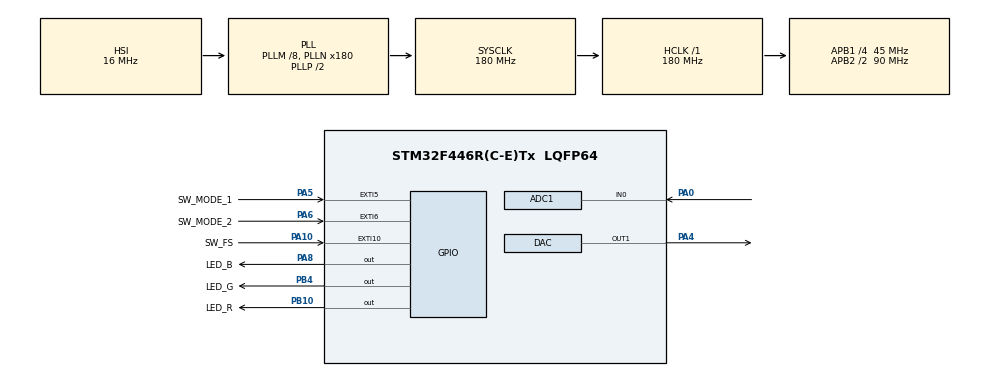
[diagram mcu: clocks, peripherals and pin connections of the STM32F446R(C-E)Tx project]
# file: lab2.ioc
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ADC1.Channel-0\#ChannelRegularConversion=ADC_CHANNEL_0
ADC1.DMAContinuousRequests=ENABLE
ADC1.ExternalTrigConv=ADC_EXTERNALTRIGCONV_T2_TRGO
ADC1.InjNumberOfConversion=0
ADC1.NbrOfConversionFlag=1
ADC1.Rank-0\#ChannelRegularConversion=1
ADC1.SamplingTime-0\#ChannelRegularConversion=ADC_SAMPLETIME_3CYCLES
ADC1.master=1
DAC.DAC_Trigger=DAC_TRIGGER_T2_TRGO
Dma.ADC1.0.Direction=DMA_PERIPH_TO_MEMORY
Dma.ADC1.0.FIFOMode=DMA_FIFOMODE_DISABLE
Dma.ADC1.0.Instance=DMA2_Stream0
Dma.ADC1.0.MemDataAlignment=DMA_MDATAALIGN_HALFWORD
Dma.ADC1.0.MemInc=DMA_MINC_ENABLE
Dma.ADC1.0.Mode=DMA_CIRCULAR
Dma.ADC1.0.PeriphDataAlignment=DMA_PDATAALIGN_HALFWORD
Dma.ADC1.0.PeriphInc=DMA_PINC_DISABLE
Dma.ADC1.0.Priority=DMA_PRIORITY_HIGH
Dma.DAC1.1.Direction=DMA_MEMORY_TO_PERIPH
Dma.DAC1.1.FIFOMode=DMA_FIFOMODE_DISABLE
Dma.DAC1.1.Instance=DMA1_Stream5
Dma.DAC1.1.MemDataAlignment=DMA_MDATAALIGN_HALFWORD
Dma.DAC1.1.MemInc=DMA_MINC_ENABLE
Dma.DAC1.1.Mode=DMA_CIRCULAR
Dma.DAC1.1.PeriphDataAlignment=DMA_PDATAALIGN_HALFWORD
Dma.DAC1.1.PeriphInc=DMA_PINC_DISABLE
Dma.DAC1.1.Priority=DMA_PRIORITY_HIGH
Dma.Request0=ADC1
Dma.Request1=DAC1
Mcu.Family=STM32F4
Mcu.Name=STM32F446R(C-E)Tx
Mcu.Package=LQFP64
NVIC.DMA1_Stream5_IRQn=true\:0\:0\:false\:false\:true\:false\:true\:true
NVIC.DMA2_Stream0_IRQn=true\:0\:0\:false\:false\:true\:false\:true\:true
NVIC.EXTI15_10_IRQn=true\:0\:0\:false\:false\:true\:true\:true\:true
NVIC.EXTI9_5_IRQn=true\:0\:0\:false\:false\:true\:true\:true\:true
NVIC.PriorityGroup=NVIC_PRIORITYGROUP_0
PA0-WKUP.Signal=ADCx_IN0
PA10.GPIO_Label=SW_FS
PA10.Signal=GPXTI10
PA13.GPIO_Label=TMS
PA13.Mode=Serial_Wire
PA13.Signal=SYS_JTMS-SWDIO
PA14.GPIO_Label=TCK
PA14.Mode=Serial_Wire
PA14.Signal=SYS_JTCK-SWCLK
PA4.Signal=COMP_DAC1_group
PA5.GPIO_Label=SW_MODE_1
PA5.Signal=GPXTI5
PA6.GPIO_Label=SW_MODE_2
PA6.Signal=GPXTI6
PA8.GPIO_Label=LED_B
PA8.Signal=GPIO_Output
PB10.GPIO_Label=LED_R
PB10.Signal=GPIO_Output
PB3.GPIO_Label=SWO
PB3.Signal=SYS_JTDO-SWO
PB4.GPIO_Label=LED_G
PB4.Signal=GPIO_Output
PC14-OSC32_IN.Mode=LSE-External-Oscillator
PC14-OSC32_IN.Signal=RCC_OSC32_IN
PC15-OSC32_OUT.Mode=LSE-External-Oscillator
PC15-OSC32_OUT.Signal=RCC_OSC32_OUT
PH0-OSC_IN.Mode=HSE-External-Oscillator
PH0-OSC_IN.Signal=RCC_OSC_IN
PH1-OSC_OUT.Mode=HSE-External-Oscillator
PH1-OSC_OUT.Signal=RCC_OSC_OUT
ProjectManager.HeapSize=0x200
ProjectManager.StackSize=0x400
ProjectManager.TargetToolchain=STM32CubeIDE
RCC.48MHZClocksFreq_Value=84000000
RCC.AHBFreq_Value=180000000
RCC.APB1CLKDivider=RCC_HCLK_DIV4
RCC.APB1Freq_Value=45000000
RCC.APB1TimFreq_Value=90000000
RCC.APB2CLKDivider=RCC_HCLK_DIV2
RCC.APB2Freq_Value=90000000
RCC.APB2TimFreq_Value=180000000
RCC.CortexFreq_Value=180000000
RCC.FLatency-AdvancedSettings=FLASH_LATENCY_5
RCC.HCLKFreq_Value=180000000
RCC.HSE_VALUE=8000000
RCC.HSI_VALUE=16000000
RCC.PLLM=8
RCC.PLLN=180
RCC.SYSCLKFreq_VALUE=180000000
RCC.SYSCLKSource=RCC_SYSCLKSOURCE_PLLCLK
RCC.USBFreq_Value=180000000
RCC.VCOOutputFreq_Value=360000000
SH.ADCx_IN0.0=ADC1_IN0,IN0
SH.COMP_DAC1_group.0=DAC_OUT1,DAC_OUT1
TIM2.AutoReloadPreload=TIM_AUTORELOAD_PRELOAD_ENABLE
TIM2.Period=11249
TIM2.TIM_MasterOutputTrigger=TIM_TRGO_UPDATE
VP_TIM2_VS_ClockSourceINT.Mode=Internal
board=NUCLEO-F446RE

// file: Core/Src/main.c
/**
 ******************************************************************************
 * @file           : main.c
 * @brief          : Real-Time Signal Acquisition and Filtering using STM32F446RE
 *
 * This program implements a real-time digital signal processing (DSP) pipeline
 * on the STM32F446RE microcontroller. It captures analog input via ADC, processes
 * the signal in Q15 fixed-point format using biquad IIR filters (LP, HP, BP, BS),
 * and outputs the result through the DAC using DMA. The sampling rate (8–48 kHz)
 * and filter type are dynamically selectable using external GPIO interrupts.
 *
 * Key Features:
 * - Double-buffered ADC/DAC using DMA for real-time throughput
 * - Q15 format filtering with CMSIS-DSP `arm_biquad_cascade_df1_q15`
 * - Dynamic selection of filter type and sampling frequency via GPIO
 * - Processing time profiling using DWT->CYCCNT
 * - Visual feedback using RGB LEDs
 *
 * Author          : Campos Mariano
 * Date            : 24/06/2025
 ******************************************************************************
 */

/* USER CODE END Header */
#include "main.h"
#include "adc.h"
#include "dac.h"
#include "dma.h"
#include "tim.h"
#include "gpio.h"
#include "arm_math.h" // CMSIS-DSP library for fixed-point processing

/* USER CODE END Includes */

/* USER CODE BEGIN PD */
#define BUFFER_SIZE 512     // Size of ADC/DAC/Q15 buffers
#define FS_8K   11249       // Auto-reload value for TIM2 to achieve ~8kHz sampling with 90 MHz clock
#define DEBOUNCE_DELAY 200	// Time anti-bounce
#define Num_coef_FPB	128
#define Num_coef_FPA	512
#define Num_coef_FPBD	1024
#define Num_coef_FRBD	1024
/* USER CODE END PD */

/* USER CODE BEGIN PM */
arm_fir_instance_q15 Filtro;
/* USER CODE END PM */

/* USER CODE BEGIN PV */
extern TIM_HandleTypeDef htim2;      // Timer used for triggering ADC/DAC
extern ADC_HandleTypeDef hadc1;      // ADC handle
extern DAC_HandleTypeDef hdac;       // DAC handle

uint16_t adc_buffer[BUFFER_SIZE];    // Raw ADC samples
uint16_t dac_buffer[BUFFER_SIZE];    // Output buffer for DAC
q15_t q15_buffer[BUFFER_SIZE];       // Intermediate Q15 format buffer
uint8_t fs_mode = 0;                 // Sampling frequency mode selector (0–5)
uint32_t time = 0;                   // Variable to store CPU cycles for processing time profiling
uint8_t filter_type = 0;			 // type of the filter LP,HP,BP,BS
uint32_t last_interrupt_time = 0;    // Time of the last interrupt anti-bouncing

uint32_t FPB_status[Num_coef_FPB + (BUFFER_SIZE/2) -1];
uint32_t FPA_status[Num_coef_FPB + (BUFFER_SIZE/2) -1];
uint32_t FPBD_status[Num_coef_FPB + (BUFFER_SIZE/2) -1];
uint32_t FRBD_status[Num_coef_FPB + (BUFFER_SIZE/2) -1];

// ===== LOWPASS Filter =====
// fs = 8000 Hz
const q15_t FIR_FPB_Coef_8K[Num_coef_FPB + 1] = {
        -4,      6,     -9,     12,    -14,     16,    -17,     16,
       -14,     11,     -6,     -2,     10,    -20,     31,    -41,
        51,    -59,     65,    -66,     64,    -56,     43,    -25,
         3,     24,    -54,     85,   -116,    143,   -166,    180,
      -186,    180,   -161,    129,    -83,     26,     42,   -117,
       195,   -273,    345,   -406,    450,   -473,    468,   -433,
       364,   -259,    119,     56,   -262,    496,   -750,   1018,
     -1292,   1563,  -1821,   2058,  -2265,   2434,  -2560,   2638,
     32767,   2638,  -2560,   2434,  -2265,   2058,  -1821,   1563,
     -1292,   1018,   -750,    496,   -262,     56,    119,   -259,
       364,   -433,    468,   -473,    450,   -406,    345,   -273,
       195,   -117,     42,     26,    -83,    129,   -161,    180,
      -186,    180,   -166,    143,   -116,     85,    -54,     24,
         3,    -25,     43,    -56,     64,    -66,     65,    -59,
        51,    -41,     31,    -20,     10,     -2,     -6,     11,
       -14,     16,    -17,     16,    -14,     12,     -9,      6,
        -4
};

// ===== LOWPASS Filter =====
// fs = 16000 Hz
const q15_t FIR_FPB_Coef_16K[Num_coef_FPB + 1] = {
       -82,    -38,     86,     65,    -82,    -96,     70,    126,
       -48,   -155,     15,    178,     28,   -193,    -79,    196,
       137,   -184,   -198,    155,    258,   -108,   -313,     42,
       356,     42,   -384,   -141,    389,    252,   -367,   -369,
       314,    485,   -227,   -593,    104,    684,     54,   -747,
      -246,    773,    467,   -751,   -714,    669,    978,   -517,
     -1251,    279,   1524,     62,  -1787,   -536,   2030,   1196,
     -2244,  -2157,   2421,   3724,  -2552,  -7036,   2633,  22392,
     32767,  22392,   2633,  -7036,  -2552,   3724,   2421,  -2157,
     -2244,   1196,   2030,   -536,  -1787,     62,   1524,    279,
     -1251,   -517,    978,    669,   -714,   -751,    467,    773,
      -246,   -747,     54,    684,    104,   -593,   -227,    485,
       314,   -369,   -367,    252,    389,   -141,   -384,     42,
       356,     42,   -313,   -108,    258,    155,   -198,   -184,
       137,    196,    -79,   -193,     28,    178,     15,   -155,
       -48,    126,     70,    -96,    -82,     65,     86,    -38,
       -82
};

// ===== LOWPASS Filter =====
// fs = 22000 Hz
const q15_t FIR_FPB_Coef_22K[Num_coef_FPB + 1] = {
      -182,   -245,    -91,    160,    289,    167,   -117,   -320,
      -251,     51,    333,    338,     38,   -321,   -420,   -147,
       281,    490,    274,   -207,   -540,   -413,     98,    562,
       556,     48,   -546,   -695,   -229,    484,    820,    443,
      -368,   -917,   -684,    190,    973,    945,     56,   -973,
     -1219,   -378,    899,   1495,    788,   -728,  -1763,  -1304,
       427,   2012,   1961,     61,  -2232,  -2842,   -856,   2414,
      4163,   2283,  -2551,  -6683,  -5641,   2635,  15786,  27876,
     32767,  27876,  15786,   2635,  -5641,  -6683,  -2551,   2283,
      4163,   2414,   -856,  -2842,  -2232,     61,   1961,   2012,
       427,  -1304,  -1763,   -728,    788,   1495,    899,   -378,
     -1219,   -973,     56,    945,    973,    190,   -684,   -917,
      -368,    443,    820,    484,   -229,   -695,   -546,     48,
       556,    562,     98,   -413,   -540,   -207,    274,    490,
       281,   -147,   -420,   -321,     38,    338,    333,     51,
      -251,   -320,   -117,    167,    289,    160,    -91,   -245,
      -182
};

// ===== LOWPASS Filter =====
// fs = 44000 Hz
const q15_t FIR_FPB_Coef_44K[Num_coef_FPB + 1] = {
      -308,   -570,   -655,   -523,   -207,    197,    558,    750,
       700,    410,    -35,   -494,   -812,   -874,   -645,   -183,
       367,    827,   1034,    903,    459,   -169,   -778,  -1163,
     -1178,   -794,   -115,    648,   1244,   1458,   1191,    499,
      -414,  -1254,  -1732,  -1655,  -1007,     41,   1165,   1989,
      2205,   1683,    529,   -927,  -2217,  -2884,  -2625,  -1418,
       443,   2407,   3813,   4090,   2955,    548,  -2550,  -5414,
     -7001,  -6413,  -3166,   2638,  10272,  18508,  25868,  30953,
     32767,  30953,  25868,  18508,  10272,   2638,  -3166,  -6413,
     -7001,  -5414,  -2550,    548,   2955,   4090,   3813,   2407,
       443,  -1418,  -2625,  -2884,  -2217,   -927,    529,   1683,
      2205,   1989,   1165,     41,  -1007,  -1655,  -1732,  -1254,
      -414,    499,   1191,   1458,   1244,    648,   -115,   -794,
     -1178,  -1163,   -778,   -169,    459,    903,   1034,    827,
       367,   -183,   -645,   -874,   -812,   -494,    -35,    410,
       700,    750,    558,    197,   -207,   -523,   -655,   -570,
      -308
};

// ===== LOWPASS Filter =====
// fs = 48000 Hz
const q15_t FIR_FPB_Coef_48K[Num_coef_FPB + 1] = {
      -343,   -666,   -848,   -839,   -632,   -264,    184,    611,
       916,   1021,    889,    541,     47,   -485,   -930,  -1180,
     -1164,   -872,   -357,    271,    871,   1300,   1445,   1257,
       760,     51,   -714,  -1358,  -1722,  -1700,  -1272,   -511,
       425,   1328,   1981,   2211,   1930,   1164,     54,  -1165,
     -2213,  -2825,  -2815,  -2124,   -844,    781,   2405,   3641,
      4144,   3696,   2270,     56,  -2550,  -4996,  -6673,  -7018,
     -5631,  -2362,   2639,   8921,  15786,  22391,  27876,  31501,
     32767,  31501,  27876,  22391,  15786,   8921,   2639,  -2362,
     -5631,  -7018,  -6673,  -4996,  -2550,     56,   2270,   3696,
      4144,   3641,   2405,    781,   -844,  -2124,  -2815,  -2825,
     -2213,  -1165,     54,   1164,   1930,   2211,   1981,   1328,
       425,   -511,  -1272,  -1700,  -1722,  -1358,   -714,     51,
       760,   1257,   1445,   1300,    871,    271,   -357,   -872,
     -1164,  -1180,   -930,   -485,     47,    541,    889,   1021,
       916,    611,    184,   -264,   -632,   -839,   -848,   -666,
      -343
};

// ===== HIGHPASS Filter =====
// fs = 8000 Hz
const q15_t FIR_FPA_Coef_8K[Num_coef_FPA + 1] = {
        -1,     -1,     -1,     -1,     -1,     -1,     -1,     -2,
        -2,     -2,     -2,     -2,     -2,     -2,     -3,     -3,
        -3,     -3,     -3,     -4,     -4,     -4,     -4,     -4,
        -5,     -5,     -5,     -5,     -5,     -6,     -6,     -6,
        -6,     -6,     -7,     -7,     -7,     -7,     -7,     -7,
        -8,     -8,     -8,     -8,     -8,     -8,     -8,     -8,
        -8,     -9,     -9,     -9,     -9,     -9,     -9,     -9,
        -9,     -8,     -8,     -8,     -8,     -8,     -8,     -8,
        -7,     -7,     -7,     -6,     -6,     -6,     -5,     -5,
        -5,     -4,     -4,     -3,     -2,     -2,     -1,     -1,
         0,      1,      1,      2,      3,      4,      5,      5,
         6,      7,      8,      9,     10,     11,     12,     13,
        14,     15,     16,     17,     18,     20,     21,     22,
        23,     24,     25,     26,     27,     29,     30,     31,
        32,     33,     34,     35,     36,     37,     38,     39,
        40,     41,     42,     43,     43,     44,     45,     45,
        46,     47,     47,     47,     48,     48,     48,     48,
        49,     49,     48,     48,     48,     48,     47,     47,
        46,     46,     45,     44,     43,     42,     41,     39,
        38,     36,     35,     33,     31,     29,     27,     25,
        23,     20,     18,     15,     12,      9,      6,      3,
         0,     -3,     -7,    -10,    -14,    -18,    -22,    -26,
       -30,    -34,    -38,    -43,    -47,    -52,    -57,    -61,
       -66,    -71,    -76,    -82,    -87,    -92,    -98,   -103,
      -108,   -114,   -120,   -125,   -131,   -137,   -143,   -148,
      -154,   -160,   -166,   -172,   -178,   -184,   -190,   -196,
      -201,   -207,   -213,   -219,   -225,   -231,   -236,   -242,
      -248,   -253,   -259,   -264,   -269,   -275,   -280,   -285,
      -290,   -295,   -300,   -304,   -309,   -313,   -318,   -322,
      -326,   -330,   -334,   -338,   -341,   -344,   -348,   -351,
      -354,   -356,   -359,   -361,   -364,   -366,   -368,   -369,
      -371,   -372,   -374,   -375,   -375,   -376,   -376,   -377,
     32767,   -377,   -376,   -376,   -375,   -375,   -374,   -372,
      -371,   -369,   -368,   -366,   -364,   -361,   -359,   -356,
      -354,   -351,   -348,   -344,   -341,   -338,   -334,   -330,
      -326,   -322,   -318,   -313,   -309,   -304,   -300,   -295,
      -290,   -285,   -280,   -275,   -269,   -264,   -259,   -253,
      -248,   -242,   -236,   -231,   -225,   -219,   -213,   -207,
      -201,   -196,   -190,   -184,   -178,   -172,   -166,   -160,
      -154,   -148,   -143,   -137,   -131,   -125,   -120,   -114,
      -108,   -103,    -98,    -92,    -87,    -82,    -76,    -71,
       -66,    -61,    -57,    -52,    -47,    -43,    -38,    -34,
       -30,    -26,    -22,    -18,    -14,    -10,     -7,     -3,
         0,      3,      6,      9,     12,     15,     18,     20,
        23,     25,     27,     29,     31,     33,     35,     36,
        38,     39,     41,     42,     43,     44,     45,     46,
        46,     47,     47,     48,     48,     48,     48,     49,
        49,     48,     48,     48,     48,     47,     47,     47,
        46,     45,     45,     44,     43,     43,     42,     41,
        40,     39,     38,     37,     36,     35,     34,     33,
        32,     31,     30,     29,     27,     26,     25,     24,
        23,     22,     21,     20,     18,     17,     16,     15,
        14,     13,     12,     11,     10,      9,      8,      7,
         6,      5,      5,      4,      3,      2,      1,      1,
         0,     -1,     -1,     -2,     -2,     -3,     -4,     -4,
        -5,     -5,     -5,     -6,     -6,     -6,     -7,     -7,
        -7,     -8,     -8,     -8,     -8,     -8,     -8,     -8,
        -9,     -9,     -9,     -9,     -9,     -9,     -9,     -9,
        -8,     -8,     -8,     -8,     -8,     -8,     -8,     -8,
        -8,     -7,     -7,     -7,     -7,     -7,     -7,     -6,
        -6,     -6,     -6,     -6,     -5,     -5,     -5,     -5,
        -5,     -4,     -4,     -4,     -4,     -4,     -3,     -3,
        -3,     -3,     -3,     -2,     -2,     -2,     -2,     -2,
        -2,     -2,     -1,     -1,     -1,     -1,     -1,     -1,
        -1
};

// ===== HIGHPASS Filter =====
// fs = 16000 Hz
const q15_t FIR_FPA_Coef_16K[Num_coef_FPA + 1] = {
         9,      9,      9,      9,      9,      9,     10,     10,
        10,     10,     10,     11,     11,     11,     11,     11,
        11,     11,     12,     12,     12,     12,     12,     12,
        12,     12,     12,     13,     13,     13,     13,     13,
        13,     13,     13,     13,     13,     13,     13,     13,
        13,     13,     13,     13,     13,     13,     12,     12,
        12,     12,     12,     12,     12,     11,     11,     11,
        11,     11,     10,     10,     10,     10,      9,      9,
         9,      8,      8,      8,      7,      7,      6,      6,
         6,      5,      5,      4,      4,      3,      3,      2,
         1,      1,      0,      0,     -1,     -2,     -2,     -3,
        -4,     -4,     -5,     -6,     -7,     -7,     -8,     -9,
       -10,    -11,    -12,    -12,    -13,    -14,    -15,    -16,
       -17,    -18,    -19,    -20,    -21,    -22,    -23,    -24,
       -25,    -26,    -28,    -29,    -30,    -31,    -32,    -33,
       -35,    -36,    -37,    -38,    -40,    -41,    -42,    -43,
       -45,    -46,    -47,    -49,    -50,    -51,    -53,    -54,
       -56,    -57,    -58,    -60,    -61,    -63,    -64,    -66,
       -67,    -69,    -70,    -72,    -73,    -75,    -76,    -78,
       -79,    -81,    -82,    -84,    -85,    -87,    -88,    -90,
       -91,    -93,    -94,    -96,    -97,    -99,   -101,   -102,
      -104,   -105,   -107,   -108,   -110,   -111,   -113,   -114,
      -116,   -117,   -119,   -120,   -122,   -123,   -125,   -126,
      -128,   -129,   -131,   -132,   -134,   -135,   -136,   -138,
      -139,   -141,   -142,   -143,   -145,   -146,   -147,   -149,
      -150,   -151,   -152,   -154,   -155,   -156,   -157,   -158,
      -160,   -161,   -162,   -163,   -164,   -165,   -166,   -167,
      -168,   -169,   -170,   -171,   -172,   -173,   -174,   -174,
      -175,   -176,   -177,   -178,   -178,   -179,   -180,   -180,
      -181,   -182,   -182,   -183,   -183,   -184,   -184,   -185,
      -185,   -186,   -186,   -186,   -187,   -187,   -187,   -188,
      -188,   -188,   -188,   -188,   -188,   -189,   -189,   -189,
     32767,   -189,   -189,   -189,   -188,   -188,   -188,   -188,
      -188,   -188,   -187,   -187,   -187,   -186,   -186,   -186,
      -185,   -185,   -184,   -184,   -183,   -183,   -182,   -182,
      -181,   -180,   -180,   -179,   -178,   -178,   -177,   -176,
      -175,   -174,   -174,   -173,   -172,   -171,   -170,   -169,
      -168,   -167,   -166,   -165,   -164,   -163,   -162,   -161,
      -160,   -158,   -157,   -156,   -155,   -154,   -152,   -151,
      -150,   -149,   -147,   -146,   -145,   -143,   -142,   -141,
      -139,   -138,   -136,   -135,   -134,   -132,   -131,   -129,
      -128,   -126,   -125,   -123,   -122,   -120,   -119,   -117,
      -116,   -114,   -113,   -111,   -110,   -108,   -107,   -105,
      -104,   -102,   -101,    -99,    -97,    -96,    -94,    -93,
       -91,    -90,    -88,    -87,    -85,    -84,    -82,    -81,
       -79,    -78,    -76,    -75,    -73,    -72,    -70,    -69,
       -67,    -66,    -64,    -63,    -61,    -60,    -58,    -57,
       -56,    -54,    -53,    -51,    -50,    -49,    -47,    -46,
       -45,    -43,    -42,    -41,    -40,    -38,    -37,    -36,
       -35,    -33,    -32,    -31,    -30,    -29,    -28,    -26,
       -25,    -24,    -23,    -22,    -21,    -20,    -19,    -18,
       -17,    -16,    -15,    -14,    -13,    -12,    -12,    -11,
       -10,     -9,     -8,     -7,     -7,     -6,     -5,     -4,
        -4,     -3,     -2,     -2,     -1,      0,      0,      1,
         1,      2,      3,      3,      4,      4,      5,      5,
         6,      6,      6,      7,      7,      8,      8,      8,
         9,      9,      9,     10,     10,     10,     10,     11,
        11,     11,     11,     11,     12,     12,     12,     12,
        12,     12,     12,     13,     13,     13,     13,     13,
        13,     13,     13,     13,     13,     13,     13,     13,
        13,     13,     13,     13,     13,     13,     12,     12,
        12,     12,     12,     12,     12,     12,     12,     11,
        11,     11,     11,     11,     11,     11,     10,     10,
        10,     10,     10,      9,      9,      9,      9,      9,
         9
};

// ===== HIGHPASS Filter =====
// fs = 24000 Hz
const q15_t FIR_FPA_Coef_22K[Num_coef_FPA + 1] = {
        -7,     -7,     -7,     -8,     -8,     -8,     -8,     -9,
        -9,     -9,    -10,    -10,    -10,    -11,    -11,    -11,
       -12,    -12,    -12,    -13,    -13,    -13,    -14,    -14,
       -15,    -15,    -15,    -16,    -16,    -16,    -17,    -17,
       -18,    -18,    -18,    -19,    -19,    -20,    -20,    -21,
       -21,    -21,    -22,    -22,    -23,    -23,    -24,    -24,
       -25,    -25,    -26,    -26,    -26,    -27,    -27,    -28,
       -28,    -29,    -29,    -30,    -30,    -31,    -31,    -32,
       -32,    -33,    -34,    -34,    -35,    -35,    -36,    -36,
       -37,    -37,    -38,    -38,    -39,    -39,    -40,    -41,
       -41,    -42,    -42,    -43,    -43,    -44,    -45,    -45,
       -46,    -46,    -47,    -47,    -48,    -49,    -49,    -50,
       -50,    -51,    -52,    -52,    -53,    -53,    -54,    -55,
       -55,    -56,    -56,    -57,    -58,    -58,    -59,    -59,
       -60,    -61,    -61,    -62,    -62,    -63,    -64,    -64,
       -65,    -65,    -66,    -67,    -67,    -68,    -69,    -69,
       -70,    -70,    -71,    -72,    -72,    -73,    -73,    -74,
       -75,    -75,    -76,    -76,    -77,    -77,    -78,    -79,
       -79,    -80,    -80,    -81,    -82,    -82,    -83,    -83,
       -84,    -84,    -85,    -85,    -86,    -87,    -87,    -88,
       -88,    -89,    -89,    -90,    -90,    -91,    -91,    -92,
       -92,    -93,    -93,    -94,    -94,    -95,    -95,    -96,
       -96,    -97,    -97,    -98,    -98,    -99,    -99,   -100,
      -100,   -101,   -101,   -102,   -102,   -102,   -103,   -103,
      -104,   -104,   -104,   -105,   -105,   -106,   -106,   -106,
      -107,   -107,   -107,   -108,   -108,   -108,   -109,   -109,
      -109,   -110,   -110,   -110,   -111,   -111,   -111,   -112,
      -112,   -112,   -112,   -113,   -113,   -113,   -113,   -114,
      -114,   -114,   -114,   -114,   -115,   -115,   -115,   -115,
      -115,   -115,   -116,   -116,   -116,   -116,   -116,   -116,
      -116,   -117,   -117,   -117,   -117,   -117,   -117,   -117,
      -117,   -117,   -117,   -117,   -117,   -117,   -117,   -117,
     32767,   -117,   -117,   -117,   -117,   -117,   -117,   -117,
      -117,   -117,   -117,   -117,   -117,   -117,   -117,   -117,
      -116,   -116,   -116,   -116,   -116,   -116,   -116,   -115,
      -115,   -115,   -115,   -115,   -115,   -114,   -114,   -114,
      -114,   -114,   -113,   -113,   -113,   -113,   -112,   -112,
      -112,   -112,   -111,   -111,   -111,   -110,   -110,   -110,
      -109,   -109,   -109,   -108,   -108,   -108,   -107,   -107,
      -107,   -106,   -106,   -106,   -105,   -105,   -104,   -104,
      -104,   -103,   -103,   -102,   -102,   -102,   -101,   -101,
      -100,   -100,    -99,    -99,    -98,    -98,    -97,    -97,
       -96,    -96,    -95,    -95,    -94,    -94,    -93,    -93,
       -92,    -92,    -91,    -91,    -90,    -90,    -89,    -89,
       -88,    -88,    -87,    -87,    -86,    -85,    -85,    -84,
       -84,    -83,    -83,    -82,    -82,    -81,    -80,    -80,
       -79,    -79,    -78,    -77,    -77,    -76,    -76,    -75,
       -75,    -74,    -73,    -73,    -72,    -72,    -71,    -70,
       -70,    -69,    -69,    -68,    -67,    -67,    -66,    -65,
       -65,    -64,    -64,    -63,    -62,    -62,    -61,    -61,
       -60,    -59,    -59,    -58,    -58,    -57,    -56,    -56,
       -55,    -55,    -54,    -53,    -53,    -52,    -52,    -51,
       -50,    -50,    -49,    -49,    -48,    -47,    -47,    -46,
       -46,    -45,    -45,    -44,    -43,    -43,    -42,    -42,
       -41,    -41,    -40,    -39,    -39,    -38,    -38,    -37,
       -37,    -36,    -36,    -35,    -35,    -34,    -34,    -33,
       -32,    -32,    -31,    -31,    -30,    -30,    -29,    -29,
       -28,    -28,    -27,    -27,    -26,    -26,    -26,    -25,
       -25,    -24,    -24,    -23,    -23,    -22,    -22,    -21,
       -21,    -21,    -20,    -20,    -19,    -19,    -18,    -18,
       -18,    -17,    -17,    -16,    -16,    -16,    -15,    -15,
       -15,    -14,    -14,    -13,    -13,    -13,    -12,    -12,
       -12,    -11,    -11,    -11,    -10,    -10,    -10,     -9,
        -9,     -9,     -8,     -8,     -8,     -8,     -7,     -7,
        -7
};

// ===== HIGHPASS Filter =====
// fs = 44000 Hz
const q15_t FIR_FPA_Coef_44K[Num_coef_FPA + 1] = {
       -27,    -27,    -28,    -28,    -28,    -28,    -29,    -29,
       -29,    -30,    -30,    -30,    -30,    -31,    -31,    -31,
       -32,    -32,    -32,    -33,    -33,    -33,    -33,    -34,
       -34,    -34,    -35,    -35,    -35,    -36,    -36,    -36,
       -37,    -37,    -37,    -37,    -38,    -38,    -38,    -39,
       -39,    -39,    -40,    -40,    -40,    -41,    -41,    -41,
       -41,    -42,    -42,    -42,    -43,    -43,    -43,    -44,
       -44,    -44,    -45,    -45,    -45,    -45,    -46,    -46,
       -46,    -47,    -47,    -47,    -48,    -48,    -48,    -48,
       -49,    -49,    -49,    -50,    -50,    -50,    -51,    -51,
       -51,    -52,    -52,    -52,    -52,    -53,    -53,    -53,
       -54,    -54,    -54,    -54,    -55,    -55,    -55,    -56,
       -56,    -56,    -57,    -57,    -57,    -57,    -58,    -58,
       -58,    -59,    -59,    -59,    -59,    -60,    -60,    -60,
       -60,    -61,    -61,    -61,    -62,    -62,    -62,    -62,
       -63,    -63,    -63,    -63,    -64,    -64,    -64,    -64,
       -65,    -65,    -65,    -65,    -66,    -66,    -66,    -66,
       -67,    -67,    -67,    -67,    -68,    -68,    -68,    -68,
       -69,    -69,    -69,    -69,    -70,    -70,    -70,    -70,
       -70,    -71,    -71,    -71,    -71,    -72,    -72,    -72,
       -72,    -72,    -73,    -73,    -73,    -73,    -73,    -74,
       -74,    -74,    -74,    -74,    -75,    -75,    -75,    -75,
       -75,    -75,    -76,    -76,    -76,    -76,    -76,    -76,
       -77,    -77,    -77,    -77,    -77,    -77,    -78,    -78,
       -78,    -78,    -78,    -78,    -78,    -79,    -79,    -79,
       -79,    -79,    -79,    -79,    -79,    -80,    -80,    -80,
       -80,    -80,    -80,    -80,    -80,    -80,    -81,    -81,
       -81,    -81,    -81,    -81,    -81,    -81,    -81,    -81,
       -81,    -82,    -82,    -82,    -82,    -82,    -82,    -82,
       -82,    -82,    -82,    -82,    -82,    -82,    -82,    -82,
       -82,    -82,    -82,    -82,    -82,    -83,    -83,    -83,
       -83,    -83,    -83,    -83,    -83,    -83,    -83,    -83,
     32767,    -83,    -83,    -83,    -83,    -83,    -83,    -83,
       -83,    -83,    -83,    -83,    -82,    -82,    -82,    -82,
       -82,    -82,    -82,    -82,    -82,    -82,    -82,    -82,
       -82,    -82,    -82,    -82,    -82,    -82,    -82,    -82,
       -81,    -81,    -81,    -81,    -81,    -81,    -81,    -81,
       -81,    -81,    -81,    -80,    -80,    -80,    -80,    -80,
       -80,    -80,    -80,    -80,    -79,    -79,    -79,    -79,
       -79,    -79,    -79,    -79,    -78,    -78,    -78,    -78,
       -78,    -78,    -78,    -77,    -77,    -77,    -77,    -77,
       -77,    -76,    -76,    -76,    -76,    -76,    -76,    -75,
       -75,    -75,    -75,    -75,    -75,    -74,    -74,    -74,
       -74,    -74,    -73,    -73,    -73,    -73,    -73,    -72,
       -72,    -72,    -72,    -72,    -71,    -71,    -71,    -71,
       -70,    -70,    -70,    -70,    -70,    -69,    -69,    -69,
       -69,    -68,    -68,    -68,    -68,    -67,    -67,    -67,
       -67,    -66,    -66,    -66,    -66,    -65,    -65,    -65,
       -65,    -64,    -64,    -64,    -64,    -63,    -63,    -63,
       -63,    -62,    -62,    -62,    -62,    -61,    -61,    -61,
       -60,    -60,    -60,    -60,    -59,    -59,    -59,    -59,
       -58,    -58,    -58,    -57,    -57,    -57,    -57,    -56,
       -56,    -56,    -55,    -55,    -55,    -54,    -54,    -54,
       -54,    -53,    -53,    -53,    -52,    -52,    -52,    -52,
       -51,    -51,    -51,    -50,    -50,    -50,    -49,    -49,
       -49,    -48,    -48,    -48,    -48,    -47,    -47,    -47,
       -46,    -46,    -46,    -45,    -45,    -45,    -45,    -44,
       -44,    -44,    -43,    -43,    -43,    -42,    -42,    -42,
       -41,    -41,    -41,    -41,    -40,    -40,    -40,    -39,
       -39,    -39,    -38,    -38,    -38,    -37,    -37,    -37,
       -37,    -36,    -36,    -36,    -35,    -35,    -35,    -34,
       -34,    -34,    -33,    -33,    -33,    -33,    -32,    -32,
       -32,    -31,    -31,    -31,    -30,    -30,    -30,    -30,
       -29,    -29,    -29,    -28,    -28,    -28,    -28,    -27,
       -27
};

// ===== HIGHPASS Filter =====
// fs = 48000 Hz
const q15_t FIR_FPA_Coef_48K[Num_coef_FPA + 1] = {
       -32,    -32,    -32,    -32,    -33,    -33,    -33,    -33,
       -34,    -34,    -34,    -34,    -34,    -35,    -35,    -35,
       -35,    -36,    -36,    -36,    -36,    -36,    -37,    -37,
       -37,    -37,    -38,    -38,    -38,    -38,    -38,    -39,
       -39,    -39,    -39,    -40,    -40,    -40,    -40,    -40,
       -41,    -41,    -41,    -41,    -42,    -42,    -42,    -42,
       -42,    -43,    -43,    -43,    -43,    -43,    -44,    -44,
       -44,    -44,    -45,    -45,    -45,    -45,    -45,    -46,
       -46,    -46,    -46,    -46,    -47,    -47,    -47,    -47,
       -47,    -48,    -48,    -48,    -48,    -48,    -49,    -49,
       -49,    -49,    -50,    -50,    -50,    -50,    -50,    -50,
       -51,    -51,    -51,    -51,    -51,    -52,    -52,    -52,
       -52,    -52,    -53,    -53,    -53,    -53,    -53,    -54,
       -54,    -54,    -54,    -54,    -54,    -55,    -55,    -55,
       -55,    -55,    -56,    -56,    -56,    -56,    -56,    -56,
       -57,    -57,    -57,    -57,    -57,    -57,    -58,    -58,
       -58,    -58,    -58,    -58,    -59,    -59,    -59,    -59,
       -59,    -59,    -60,    -60,    -60,    -60,    -60,    -60,
       -60,    -61,    -61,    -61,    -61,    -61,    -61,    -61,
       -62,    -62,    -62,    -62,    -62,    -62,    -62,    -63,
       -63,    -63,    -63,    -63,    -63,    -63,    -63,    -64,
       -64,    -64,    -64,    -64,    -64,    -64,    -64,    -65,
       -65,    -65,    -65,    -65,    -65,    -65,    -65,    -65,
       -66,    -66,    -66,    -66,    -66,    -66,    -66,    -66,
       -66,    -66,    -66,    -67,    -67,    -67,    -67,    -67,
       -67,    -67,    -67,    -67,    -67,    -67,    -67,    -67,
       -68,    -68,    -68,    -68,    -68,    -68,    -68,    -68,
       -68,    -68,    -68,    -68,    -68,    -68,    -68,    -68,
       -68,    -69,    -69,    -69,    -69,    -69,    -69,    -69,
       -69,    -69,    -69,    -69,    -69,    -69,    -69,    -69,
       -69,    -69,    -69,    -69,    -69,    -69,    -69,    -69,
       -69,    -69,    -69,    -69,    -69,    -69,    -69,    -69,
     32767,    -69,    -69,    -69,    -69,    -69,    -69,    -69,
       -69,    -69,    -69,    -69,    -69,    -69,    -69,    -69,
       -69,    -69,    -69,    -69,    -69,    -69,    -69,    -69,
       -69,    -69,    -69,    -69,    -69,    -69,    -69,    -69,
       -68,    -68,    -68,    -68,    -68,    -68,    -68,    -68,
       -68,    -68,    -68,    -68,    -68,    -68,    -68,    -68,
       -68,    -67,    -67,    -67,    -67,    -67,    -67,    -67,
       -67,    -67,    -67,    -67,    -67,    -67,    -66,    -66,
       -66,    -66,    -66,    -66,    -66,    -66,    -66,    -66,
       -66,    -65,    -65,    -65,    -65,    -65,    -65,    -65,
       -65,    -65,    -64,    -64,    -64,    -64,    -64,    -64,
       -64,    -64,    -63,    -63,    -63,    -63,    -63,    -63,
       -63,    -63,    -62,    -62,    -62,    -62,    -62,    -62,
       -62,    -61,    -61,    -61,    -61,    -61,    -61,    -61,
       -60,    -60,    -60,    -60,    -60,    -60,    -60,    -59,
       -59,    -59,    -59,    -59,    -59,    -58,    -58,    -58,
       -58,    -58,    -58,    -57,    -57,    -57,    -57,    -57,
       -57,    -56,    -56,    -56,    -56,    -56,    -56,    -55,
       -55,    -55,    -55,    -55,    -54,    -54,    -54,    -54,
       -54,    -54,    -53,    -53,    -53,    -53,    -53,    -52,
       -52,    -52,    -52,    -52,    -51,    -51,    -51,    -51,
       -51,    -50,    -50,    -50,    -50,    -50,    -50,    -49,
       -49,    -49,    -49,    -48,    -48,    -48,    -48,    -48,
       -47,    -47,    -47,    -47,    -47,    -46,    -46,    -46,
       -46,    -46,    -45,    -45,    -45,    -45,    -45,    -44,
       -44,    -44,    -44,    -43,    -43,    -43,    -43,    -43,
       -42,    -42,    -42,    -42,    -42,    -41,    -41,    -41,
       -41,    -40,    -40,    -40,    -40,    -40,    -39,    -39,
       -39,    -39,    -38,    -38,    -38,    -38,    -38,    -37,
       -37,    -37,    -37,    -36,    -36,    -36,    -36,    -36,
       -35,    -35,    -35,    -35,    -34,    -34,    -34,    -34,
       -34,    -33,    -33,    -33,    -33,    -32,    -32,    -32,
       -32
};

// ===== BANDPASS Filter =====
// fs = 8000 Hz
const q15_t FIR_FPBD_Coef_8K[Num_coef_FPBD + 1] = {
        -1,     -2,     -2,     -1,     -3,      0,     -3,      0,
        -3,      0,     -3,     -1,     -1,     -2,      0,     -3,
         1,     -3,      1,     -3,      0,     -1,     -1,      0,
        -2,      1,     -2,      2,     -2,      1,     -1,      1,
         0,     -1,      1,     -2,      2,     -2,      3,     -1,
         2,      0,      1,      2,      0,      3,     -1,      4,
        -1,      4,      0,      3,      2,      1,      4,      0,
         5,      0,      5,      0,      4,      2,      3,      4,
         1,      5,      0,      6,      0,      6,      1,      4,
         3,      2,      5,      1,      7,      0,      7,      1,
         6,      2,      3,      5,      1,      7,      0,      7,
        -1,      7,      1,      4,      3,      2,      5,     -1,
         7,     -2,      7,     -1,      5,      1,      2,      3,
        -1,      5,     -4,      6,     -4,      5,     -3,      2,
         0,     -2,      3,     -5,      5,     -7,      4,     -6,
         2,     -4,     -2,     -1,     -7,      2,     -9,      3,
       -10,      1,     -8,     -3,     -5,     -7,     -1,    -11,
         1,    -13,      1,    -13,     -2,     -9,     -7,     -5,
       -12,     -1,    -16,      0,    -16,     -2,    -13,     -6,
        -9,    -11,     -4,    -16,      0,    -18,      0,    -17,
        -3,    -12,     -9,     -6,    -15,     -1,    -18,      2,
       -18,      0,    -14,     -5,     -8,    -11,     -1,    -16,
         4,    -18,      5,    -15,      2,     -9,     -5,      0,
       -11,      7,    -15,     10,    -14,      9,     -9,      4,
         0,     -4,      9,    -10,     15,    -11,     17,     -8,
        13,      1,      6,     11,     -2,     20,     -7,     24,
        -6,     23,      1,     16,     12,      7,     22,      0,
        30,     -3,     31,      1,     26,     11,     17,     23,
         7,     33,      0,     37,      1,     35,      8,     26,
        20,     14,     32,      4,     40,      0,     40,      3,
        33,     14,     20,     27,      7,     38,     -2,     42,
        -3,     37,      4,     25,     17,      9,     30,     -5,
        38,    -11,     37,     -8,     27,      3,     10,     17,
        -7,     29,    -19,     33,    -22,     26,    -14,     10,
         0,    -10,     15,    -27,     24,    -36,     22,    -33,
         9,    -20,    -12,     -3,    -33,     10,    -48,     15,
       -51,      6,    -42,    -13,    -24,    -36,     -6,    -56,
         5,    -66,      4,    -61,    -11,    -45,    -35,    -24,
       -59,     -6,    -75,      1,    -76,     -7,    -64,    -28,
       -41,    -54,    -17,    -76,     -2,    -85,     -1,    -77,
       -16,    -55,    -41,    -27,    -67,     -3,    -83,      8,
       -83,      1,    -65,    -21,    -34,    -49,     -3,    -72,
        18,    -79,     22,    -67,      7,    -38,    -20,     -2,
       -49,     29,    -66,     45,    -62,     39,    -38,     16,
         0,    -16,     40,    -42,     67,    -49,     73,    -34,
        56,      2,     25,     47,     -9,     86,    -29,    105,
       -25,     98,      4,     69,     50,     30,     97,     -2,
       129,    -12,    135,      5,    113,     46,     72,     98,
        29,    142,      2,    162,      3,    151,     35,    112,
        86,     60,    140,     16,    174,     -2,    177,     14,
       145,     60,     89,    118,     30,    167,    -10,    186,
       -15,    166,     18,    111,     76,     40,    136,    -21,
       174,    -51,    171,    -38,    124,     13,     47,     81,
       -35,    137,    -92,    155,   -105,    124,    -69,     48,
         0,    -49,     73,   -134,    117,   -178,    109,   -166,
        43,   -104,    -62,    -18,   -173,     54,   -253,     77,
      -273,     34,   -227,    -69,   -134,   -202,    -34,   -320,
        29,   -381,     21,   -364,    -67,   -274,   -212,   -148,
      -369,    -38,   -482,      5,   -509,    -50,   -437,   -195,
      -290,   -389,   -125,   -566,    -12,   -658,     -7,   -625,
      -132,   -469,   -359,   -241,   -616,    -27,   -811,     79,
      -858,     12,   -717,   -237,   -414,   -609,    -40,   -985,
       266,  -1216,    359,  -1171,    131,   -777,   -449,    -48,
     -1317,    902,  -2319,   1892,  -3254,   2709,  -3915,   3170,
     32767,   3170,  -3915,   2709,  -3254,   1892,  -2319,    902,
     -1317,    -48,   -449,   -777,    131,  -1171,    359,  -1216,
       266,   -985,    -40,   -609,   -414,   -237,   -717,     12,
      -858,     79,   -811,    -27,   -616,   -241,   -359,   -469,
      -132,   -625,     -7,   -658,    -12,   -566,   -125,   -389,
      -290,   -195,   -437,    -50,   -509,      5,   -482,    -38,
      -369,   -148,   -212,   -274,    -67,   -364,     21,   -381,
        29,   -320,    -34,   -202,   -134,    -69,   -227,     34,
      -273,     77,   -253,     54,   -173,    -18,    -62,   -104,
        43,   -166,    109,   -178,    117,   -134,     73,    -49,
         0,     48,    -69,    124,   -105,    155,    -92,    137,
       -35,     81,     47,     13,    124,    -38,    171,    -51,
       174,    -21,    136,     40,     76,    111,     18,    166,
       -15,    186,    -10,    167,     30,    118,     89,     60,
       145,     14,    177,     -2,    174,     16,    140,     60,
        86,    112,     35,    151,      3,    162,      2,    142,
        29,     98,     72,     46,    113,      5,    135,    -12,
       129,     -2,     97,     30,     50,     69,      4,     98,
       -25,    105,    -29,     86,     -9,     47,     25,      2,
        56,    -34,     73,    -49,     67,    -42,     40,    -16,
         0,     16,    -38,     39,    -62,     45,    -66,     29,
       -49,     -2,    -20,    -38,      7,    -67,     22,    -79,
        18,    -72,     -3,    -49,    -34,    -21,    -65,      1,
       -83,      8,    -83,     -3,    -67,    -27,    -41,    -55,
       -16,    -77,     -1,    -85,     -2,    -76,    -17,    -54,
       -41,    -28,    -64,     -7,    -76,      1,    -75,     -6,
       -59,    -24,    -35,    -45,    -11,    -61,      4,    -66,
         5,    -56,     -6,    -36,    -24,    -13,    -42,      6,
       -51,     15,    -48,     10,    -33,     -3,    -12,    -20,
         9,    -33,     22,    -36,     24,    -27,     15,    -10,
         0,     10,    -14,     26,    -22,     33,    -19,     29,
        -7,     17,     10,      3,     27,     -8,     37,    -11,
        38,     -5,     30,      9,     17,     25,      4,     37,
        -3,     42,     -2,     38,      7,     27,     20,     14,
        33,      3,     40,      0,     40,      4,     32,     14,
        20,     26,      8,     35,      1,     37,      0,     33,
         7,     23,     17,     11,     26,      1,     31,     -3,
        30,      0,     22,      7,     12,     16,      1,     23,
        -6,     24,     -7,     20,     -2,     11,      6,      1,
        13,     -8,     17,    -11,     15,    -10,      9,     -4,
         0,      4,     -9,      9,    -14,     10,    -15,      7,
       -11,      0,     -5,     -9,      2,    -15,      5,    -18,
         4,    -16,     -1,    -11,     -8,     -5,    -14,      0,
       -18,      2,    -18,     -1,    -15,     -6,     -9,    -12,
        -3,    -17,      0,    -18,      0,    -16,     -4,    -11,
        -9,     -6,    -13,     -2,    -16,      0,    -16,     -1,
       -12,     -5,     -7,     -9,     -2,    -13,      1,    -13,
         1,    -11,     -1,     -7,     -5,     -3,     -8,      1,
       -10,      3,     -9,      2,     -7,     -1,     -2,     -4,
         2,     -6,      4,     -7,      5,     -5,      3,     -2,
         0,      2,     -3,      5,     -4,      6,     -4,      5,
        -1,      3,      2,      1,      5,     -1,      7,     -2,
         7,     -1,      5,      2,      3,      4,      1,      7,
        -1,      7,      0,      7,      1,      5,      3,      2,
         6,      1,      7,      0,      7,      1,      5,      2,
         3,      4,      1,      6,      0,      6,      0,      5,
         1,      4,      3,      2,      4,      0,      5,      0,
         5,      0,      4,      1,      2,      3,      0,      4,
        -1,      4,     -1,      3,      0,      2,      1,      0,
         2,     -1,      3,     -2,      2,     -2,      1,     -1,
         0,      1,     -1,      1,     -2,      2,     -2,      1,
        -2,      0,     -1,     -1,      0,     -3,      1,     -3,
         1,     -3,      0,     -2,     -1,     -1,     -3,      0,
        -3,      0,     -3,      0,     -3,     -1,     -2,     -2,
        -1
};

// ===== BANDPASS Filter =====
// fs = 16000 Hz
const q15_t FIR_FPBD_Coef_16K[Num_coef_FPBD + 1] = {
         6,      2,     -2,      1,      5,      4,     -1,     -1,
         4,      5,      0,     -2,      1,      5,      3,     -2,
        -1,      4,      4,     -1,     -3,      1,      5,      1,
        -3,     -1,      4,      3,     -2,     -4,      1,      4,
         0,     -4,     -2,      4,      2,     -4,     -4,      1,
         4,     -2,     -6,     -2,      3,      1,     -5,     -5,
         1,      3,     -3,     -7,     -2,      3,     -1,     -7,
        -6,      1,      2,     -5,     -8,     -2,      3,     -2,
        -9,     -6,      1,      0,     -8,    -10,     -2,      2,
        -5,    -11,     -7,      1,     -1,    -10,    -11,     -2,
         1,     -7,    -14,     -8,      1,     -3,    -13,    -13,
        -2,      0,    -10,    -16,     -8,      0,     -5,    -16,
       -14,     -2,     -1,    -13,    -18,     -8,      0,     -8,
       -19,    -14,     -2,     -3,    -16,    -20,     -7,      0,
       -11,    -22,    -15,     -1,     -5,    -20,    -21,     -6,
         0,    -14,    -24,    -14,      0,     -7,    -23,    -22,
        -5,     -1,    -17,    -26,    -13,      1,     -8,    -26,
       -21,     -3,     -1,    -20,    -27,    -11,      3,    -10,
       -28,    -20,      0,     -1,    -22,    -28,     -7,      5,
       -12,    -30,    -18,      4,     -1,    -25,    -27,     -3,
         7,    -14,    -30,    -14,      9,     -1,    -26,    -24,
         3,     10,    -15,    -30,     -8,     14,     -1,    -27,
       -20,     10,     12,    -16,    -28,     -1,     19,      0,
       -27,    -15,     17,     15,    -17,    -25,      7,     26,
         0,    -26,     -7,     26,     19,    -17,    -20,     17,
        32,      1,    -24,      2,     36,     22,    -17,    -13,
        28,     39,      1,    -20,     13,     46,     24,    -15,
        -5,     40,     45,      2,    -15,     25,     56,     27,
       -13,      6,     53,     51,      2,     -9,     38,     66,
        28,    -11,     17,     67,     56,      3,     -1,     53,
        75,     29,     -7,     30,     80,     59,      3,      8,
        68,     83,     28,     -3,     44,     93,     61,      3,
        18,     83,     89,     26,      1,     59,    104,     60,
         2,     29,     98,     93,     23,      6,     74,    113,
        57,      1,     40,    111,     94,     17,     11,     88,
       119,     51,     -1,     52,    123,     91,     10,     16,
       102,    122,     42,     -4,     63,    132,     85,      1,
        22,    114,    121,     30,     -7,     74,    137,     74,
       -11,     26,    124,    116,     14,    -11,     84,    138,
        58,    -24,     31,    130,    105,     -6,    -16,     92,
       135,     37,    -40,     34,    134,     88,    -30,    -22,
        98,    126,     11,    -57,     37,    133,     65,    -56,
       -28,    102,    111,    -21,    -75,     39,    128,     36,
       -86,    -35,    103,     90,    -57,    -95,     40,    117,
         0,   -119,    -41,    100,     62,    -99,   -114,     40,
       100,    -42,   -153,    -48,     94,     27,   -144,   -134,
        38,     77,    -91,   -189,    -54,     84,    -16,   -193,
      -153,     35,     48,   -145,   -225,    -59,     69,    -65,
      -245,   -170,     31,     12,   -205,   -260,    -62,     50,
      -122,   -298,   -184,     26,    -31,   -269,   -293,    -64,
        27,   -186,   -352,   -194,     19,    -81,   -338,   -323,
       -62,     -2,   -256,   -405,   -199,     12,   -139,   -410,
      -348,    -57,    -36,   -333,   -456,   -197,      5,   -204,
      -484,   -365,    -47,    -75,   -417,   -504,   -187,     -3,
      -278,   -560,   -374,    -31,   -120,   -508,   -546,   -165,
       -11,   -361,   -637,   -370,     -7,   -173,   -607,   -580,
      -129,    -19,   -457,   -716,   -351,     28,   -236,   -718,
      -604,    -73,    -27,   -570,   -796,   -309,     78,   -312,
      -845,   -614,     12,    -34,   -708,   -881,   -234,    151,
      -410,  -1000,   -603,    142,    -40,   -891,   -977,   -106,
       264,   -548,  -1209,   -560,    357,    -45,  -1166,  -1102,
       130,    462,   -774,  -1548,   -448,    769,    -48,  -1681,
     -1315,    652,    901,  -1276,  -2317,   -124,   1890,    -51,
     -3252,  -1984,   2708,   2863,  -3914,  -7442,   3170,  22754,
     32767,  22754,   3170,  -7442,  -3914,   2863,   2708,  -1984,
     -3252,    -51,   1890,   -124,  -2317,  -1276,    901,    652,
     -1315,  -1681,    -48,    769,   -448,  -1548,   -774,    462,
       130,  -1102,  -1166,    -45,    357,   -560,  -1209,   -548,
       264,   -106,   -977,   -891,    -40,    142,   -603,  -1000,
      -410,    151,   -234,   -881,   -708,    -34,     12,   -614,
      -845,   -312,     78,   -309,   -796,   -570,    -27,    -73,
      -604,   -718,   -236,     28,   -351,   -716,   -457,    -19,
      -129,   -580,   -607,   -173,     -7,   -370,   -637,   -361,
       -11,   -165,   -546,   -508,   -120,    -31,   -374,   -560,
      -278,     -3,   -187,   -504,   -417,    -75,    -47,   -365,
      -484,   -204,      5,   -197,   -456,   -333,    -36,    -57,
      -348,   -410,   -139,     12,   -199,   -405,   -256,     -2,
       -62,   -323,   -338,    -81,     19,   -194,   -352,   -186,
        27,    -64,   -293,   -269,    -31,     26,   -184,   -298,
      -122,     50,    -62,   -260,   -205,     12,     31,   -170,
      -245,    -65,     69,    -59,   -225,   -145,     48,     35,
      -153,   -193,    -16,     84,    -54,   -189,    -91,     77,
        38,   -134,   -144,     27,     94,    -48,   -153,    -42,
       100,     40,   -114,    -99,     62,    100,    -41,   -119,
         0,    117,     40,    -95,    -57,     90,    103,    -35,
       -86,     36,    128,     39,    -75,    -21,    111,    102,
       -28,    -56,     65,    133,     37,    -57,     11,    126,
        98,    -22,    -30,     88,    134,     34,    -40,     37,
       135,     92,    -16,     -6,    105,    130,     31,    -24,
        58,    138,     84,    -11,     14,    116,    124,     26,
       -11,     74,    137,     74,     -7,     30,    121,    114,
        22,      1,     85,    132,     63,     -4,     42,    122,
       102,     16,     10,     91,    123,     52,     -1,     51,
       119,     88,     11,     17,     94,    111,     40,      1,
        57,    113,     74,      6,     23,     93,     98,     29,
         2,     60,    104,     59,      1,     26,     89,     83,
        18,      3,     61,     93,     44,     -3,     28,     83,
        68,      8,      3,     59,     80,     30,     -7,     29,
        75,     53,     -1,      3,     56,     67,     17,    -11,
        28,     66,     38,     -9,      2,     51,     53,      6,
       -13,     27,     56,     25,    -15,      2,     45,     40,
        -5,    -15,     24,     46,     13,    -20,      1,     39,
        28,    -13,    -17,     22,     36,      2,    -24,      1,
        32,     17,    -20,    -17,     19,     26,     -7,    -26,
         0,     26,      7,    -25,    -17,     15,     17,    -15,
       -27,      0,     19,     -1,    -28,    -16,     12,     10,
       -20,    -27,     -1,     14,     -8,    -30,    -15,     10,
         3,    -24,    -26,     -1,      9,    -14,    -30,    -14,
         7,     -3,    -27,    -25,     -1,      4,    -18,    -30,
       -12,      5,     -7,    -28,    -22,     -1,      0,    -20,
       -28,    -10,      3,    -11,    -27,    -20,     -1,     -3,
       -21,    -26,     -8,      1,    -13,    -26,    -17,     -1,
        -5,    -22,    -23,     -7,      0,    -14,    -24,    -14,
         0,     -6,    -21,    -20,     -5,     -1,    -15,    -22,
       -11,      0,     -7,    -20,    -16,     -3,     -2,    -14,
       -19,     -8,      0,     -8,    -18,    -13,     -1,     -2,
       -14,    -16,     -5,      0,     -8,    -16,    -10,      0,
        -2,    -13,    -13,     -3,      1,     -8,    -14,     -7,
         1,     -2,    -11,    -10,     -1,      1,     -7,    -11,
        -5,      2,     -2,    -10,     -8,      0,      1,     -6,
        -9,     -2,      3,     -2,     -8,     -5,      2,      1,
        -6,     -7,     -1,      3,     -2,     -7,     -3,      3,
         1,     -5,     -5,      1,      3,     -2,     -6,     -2,
         4,      1,     -4,     -4,      2,      4,     -2,     -4,
         0,      4,      1,     -4,     -2,      3,      4,     -1,
        -3,      1,      5,      1,     -3,     -1,      4,      4,
        -1,     -2,      3,      5,      1,     -2,      0,      5,
         4,     -1,     -1,      4,      5,      1,     -2,      2,
         6
};

// ===== BANDPASS Filter =====
// fs = 24000 Hz
const q15_t FIR_FPBD_Coef_22K[Num_coef_FPBD + 1] = {
        -7,     -7,     -2,      2,      3,      0,     -5,     -7,
        -5,      0,      4,      3,     -1,     -6,     -7,     -3,
         2,      5,      2,     -3,     -7,     -6,     -1,      4,
         5,      1,     -4,     -7,     -4,      2,      6,      5,
         0,     -5,     -6,     -2,      4,      7,      5,     -2,
        -6,     -5,      1,      7,      8,      4,     -3,     -6,
        -3,      4,      9,      8,      2,     -4,     -5,      0,
         7,     11,      8,      0,     -5,     -4,      3,     11,
        12,      7,     -1,     -5,     -1,      7,     14,     13,
         5,     -3,     -4,      2,     12,     16,     12,      3,
        -4,     -2,      7,     16,     18,     11,      1,     -4,
         1,     12,     20,     19,      9,     -1,     -3,      6,
        18,     24,     18,      6,     -2,      0,     11,     23,
        26,     17,      4,     -3,      4,     18,     29,     27,
        14,      1,     -1,     10,     25,     33,     26,     11,
        -1,      2,     17,     32,     35,     24,      7,     -1,
         7,     25,     39,     36,     20,      3,      0,     14,
        34,     43,     35,     15,      1,      4,     23,     42,
        46,     31,     10,      0,     10,     33,     50,     47,
        26,      5,      1,     19,     43,     55,     44,     19,
         1,      5,     29,     53,     58,     39,     12,     -1,
        12,     40,     61,     57,     31,      5,      0,     22,
        52,     67,     53,     22,     -1,      4,     33,     63,
        69,     45,     12,     -4,     12,     46,     72,     67,
        35,      2,     -4,     22,     60,     77,     60,     22,
        -6,      0,     35,     71,     78,     49,      8,    -12,
         7,     50,     81,     74,     35,     -6,    -13,     19,
        64,     85,     64,     17,    -17,    -10,     33,     77,
        85,     49,     -1,    -25,     -2,     49,     86,     78,
        30,    -19,    -29,     10,     64,     90,     64,      7,
       -35,    -27,     25,     78,     87,     44,    -17,    -46,
       -19,     42,     87,     77,     19,    -41,    -52,     -7,
        59,     90,     58,    -11,    -61,    -52,     10,     73,
        84,     32,    -41,    -77,    -44,     29,     83,     70,
         0,    -71,    -86,    -31,     48,     84,     46,    -37,
       -97,    -86,    -12,     63,     76,     13,    -75,   -117,
       -79,      9,     72,     57,    -27,   -112,   -129,    -64,
        30,     73,     28,    -72,   -144,   -131,    -43,     47,
        62,    -13,   -118,   -169,   -123,    -19,     57,     39,
       -61,   -163,   -184,   -106,      5,     57,      3,   -115,
      -202,   -187,    -81,     26,     44,    -45,   -172,   -232,
      -177,    -53,     38,     16,   -103,   -225,   -250,   -157,
       -24,     38,    -27,   -168,   -272,   -253,   -127,      1,
        23,    -83,   -234,   -307,   -241,    -92,     17,     -9,
      -152,   -298,   -327,   -215,    -55,     19,    -58,   -228,
      -352,   -329,   -178,    -23,      3,   -125,   -306,   -393,
      -313,   -133,     -2,    -32,   -204,   -380,   -415,   -280,
       -86,      4,    -89,   -293,   -444,   -416,   -232,    -43,
       -10,   -165,   -385,   -491,   -394,   -173,    -12,    -49,
      -259,   -473,   -516,   -349,   -111,      1,   -113,   -364,
      -549,   -514,   -286,    -53,    -11,   -202,   -473,   -604,
      -483,   -208,     -7,    -51,   -312,   -579,   -632,   -423,
      -123,     18,   -123,   -438,   -671,   -626,   -337,    -41,
        14,   -227,   -573,   -739,   -584,   -230,     29,    -26,
      -361,   -705,   -773,   -502,   -111,     75,   -107,   -519,
      -824,   -765,   -383,     12,     87,   -233,   -693,   -916,
      -708,   -230,    124,     52,   -403,   -874,   -968,   -594,
       -50,    213,    -39,   -616,  -1047,   -965,   -420,    148,
       262,   -197,   -869,  -1198,   -892,   -181,    354,    252,
      -435,  -1158,  -1309,   -729,    130,    556,    161,   -770,
     -1483,  -1358,   -446,    529,    741,    -48,  -1242,  -1854,
     -1311,     19,   1065,    899,   -455,  -1952,  -2314,  -1096,
       835,   1888,   1020,  -1295,  -3250,  -3050,   -460,   2707,
      3729,   1095,  -3914,  -7511,  -5642,   3170,  16304,  28062,
     32767,  28062,  16304,   3170,  -5642,  -7511,  -3914,   1095,
      3729,   2707,   -460,  -3050,  -3250,  -1295,   1020,   1888,
       835,  -1096,  -2314,  -1952,   -455,    899,   1065,     19,
     -1311,  -1854,  -1242,    -48,    741,    529,   -446,  -1358,
     -1483,   -770,    161,    556,    130,   -729,  -1309,  -1158,
      -435,    252,    354,   -181,   -892,  -1198,   -869,   -197,
       262,    148,   -420,   -965,  -1047,   -616,    -39,    213,
       -50,   -594,   -968,   -874,   -403,     52,    124,   -230,
      -708,   -916,   -693,   -233,     87,     12,   -383,   -765,
      -824,   -519,   -107,     75,   -111,   -502,   -773,   -705,
      -361,    -26,     29,   -230,   -584,   -739,   -573,   -227,
        14,    -41,   -337,   -626,   -671,   -438,   -123,     18,
      -123,   -423,   -632,   -579,   -312,    -51,     -7,   -208,
      -483,   -604,   -473,   -202,    -11,    -53,   -286,   -514,
      -549,   -364,   -113,      1,   -111,   -349,   -516,   -473,
      -259,    -49,    -12,   -173,   -394,   -491,   -385,   -165,
       -10,    -43,   -232,   -416,   -444,   -293,    -89,      4,
       -86,   -280,   -415,   -380,   -204,    -32,     -2,   -133,
      -313,   -393,   -306,   -125,      3,    -23,   -178,   -329,
      -352,   -228,    -58,     19,    -55,   -215,   -327,   -298,
      -152,     -9,     17,    -92,   -241,   -307,   -234,    -83,
        23,      1,   -127,   -253,   -272,   -168,    -27,     38,
       -24,   -157,   -250,   -225,   -103,     16,     38,    -53,
      -177,   -232,   -172,    -45,     44,     26,    -81,   -187,
      -202,   -115,      3,     57,      5,   -106,   -184,   -163,
       -61,     39,     57,    -19,   -123,   -169,   -118,    -13,
        62,     47,    -43,   -131,   -144,    -72,     28,     73,
        30,    -64,   -129,   -112,    -27,     57,     72,      9,
       -79,   -117,    -75,     13,     76,     63,    -12,    -86,
       -97,    -37,     46,     84,     48,    -31,    -86,    -71,
         0,     70,     83,     29,    -44,    -77,    -41,     32,
        84,     73,     10,    -52,    -61,    -11,     58,     90,
        59,     -7,    -52,    -41,     19,     77,     87,     42,
       -19,    -46,    -17,     44,     87,     78,     25,    -27,
       -35,      7,     64,     90,     64,     10,    -29,    -19,
        30,     78,     86,     49,     -2,    -25,     -1,     49,
        85,     77,     33,    -10,    -17,     17,     64,     85,
        64,     19,    -13,     -6,     35,     74,     81,     50,
         7,    -12,      8,     49,     78,     71,     35,      0,
        -6,     22,     60,     77,     60,     22,     -4,      2,
        35,     67,     72,     46,     12,     -4,     12,     45,
        69,     63,     33,      4,     -1,     22,     53,     67,
        52,     22,      0,      5,     31,     57,     61,     40,
        12,     -1,     12,     39,     58,     53,     29,      5,
         1,     19,     44,     55,     43,     19,      1,      5,
        26,     47,     50,     33,     10,      0,     10,     31,
        46,     42,     23,      4,      1,     15,     35,     43,
        34,     14,      0,      3,     20,     36,     39,     25,
         7,     -1,      7,     24,     35,     32,     17,      2,
        -1,     11,     26,     33,     25,     10,     -1,      1,
        14,     27,     29,     18,      4,     -3,      4,     17,
        26,     23,     11,      0,     -2,      6,     18,     24,
        18,      6,     -3,     -1,      9,     19,     20,     12,
         1,     -4,      1,     11,     18,     16,      7,     -2,
        -4,      3,     12,     16,     12,      2,     -4,     -3,
         5,     13,     14,      7,     -1,     -5,     -1,      7,
        12,     11,      3,     -4,     -5,      0,      8,     11,
         7,      0,     -5,     -4,      2,      8,      9,      4,
        -3,     -6,     -3,      4,      8,      7,      1,     -5,
        -6,     -2,      5,      7,      4,     -2,     -6,     -5,
         0,      5,      6,      2,     -4,     -7,     -4,      1,
         5,      4,     -1,     -6,     -7,     -3,      2,      5,
         2,     -3,     -7,     -6,     -1,      3,      4,      0,
        -5,     -7,     -5,      0,      3,      2,     -2,     -7,
        -7
};

// ===== BANDPASS Filter =====
// fs = 40000 Hz
const q15_t FIR_FPBD_Coef_44K[Num_coef_FPBD + 1] = {
        11,      6,      2,     -2,     -2,      0,      5,     10,
        14,     16,     15,     12,      7,      2,     -2,     -3,
        -1,      4,      9,     14,     16,     16,     12,      7,
         2,     -3,     -4,     -2,      3,      8,     14,     17,
        17,     13,      8,      2,     -3,     -5,     -3,      1,
         8,     14,     18,     18,     14,      8,      2,     -4,
        -7,     -5,      0,      7,     14,     18,     19,     16,
         9,      2,     -5,     -8,     -7,     -2,      6,     14,
        19,     21,     17,     10,      1,     -6,    -11,    -10,
        -5,      4,     13,     20,     22,     19,     11,      1,
        -8,    -13,    -13,     -8,      2,     12,     21,     24,
        21,     12,      1,    -10,    -17,    -18,    -12,     -1,
        11,     21,     25,     23,     13,      1,    -12,    -21,
       -23,    -17,     -5,      9,     21,     27,     24,     15,
         0,    -15,    -26,    -29,    -23,    -10,      6,     20,
        27,     26,     16,     -1,    -18,    -31,    -36,    -30,
       -16,      2,     18,     28,     27,     16,     -2,    -22,
       -37,    -44,    -39,    -24,     -4,     16,     28,     29,
        17,     -3,    -26,    -44,    -53,    -49,    -33,    -10,
        12,     27,     29,     18,     -4,    -30,    -52,    -64,
       -60,    -44,    -19,      7,     25,     29,     18,     -6,
       -35,    -61,    -75,    -74,    -56,    -29,      1,     22,
        29,     18,     -7,    -40,    -70,    -88,    -89,    -71,
       -41,     -7,     19,     28,     18,     -9,    -46,    -81,
      -103,   -106,    -88,    -55,    -17,     13,     26,     18,
       -11,    -52,    -92,   -118,   -124,   -106,    -71,    -29,
         7,     24,     17,    -13,    -58,   -103,   -135,   -144,
      -127,    -90,    -43,     -1,     21,     16,    -16,    -64,
      -115,   -153,   -167,   -151,   -111,    -59,    -11,     16,
        14,    -18,    -70,   -127,   -172,   -190,   -176,   -134,
       -77,    -23,     11,     12,    -20,    -76,   -140,   -192,
      -216,   -204,   -160,    -98,    -36,      4,     10,    -21,
       -81,   -152,   -212,   -243,   -234,   -189,   -121,    -52,
        -3,      8,    -22,    -86,   -164,   -233,   -271,   -267,
      -220,   -147,    -69,    -12,      6,    -23,    -90,   -176,
      -254,   -301,   -301,   -255,   -176,    -89,    -22,      3,
       -23,    -93,   -187,   -275,   -332,   -338,   -292,   -207,
      -111,    -33,      1,    -22,    -94,   -196,   -296,   -364,
      -377,   -332,   -242,   -135,    -45,     -2,    -19,    -94,
      -204,   -316,   -396,   -418,   -374,   -279,   -162,    -59,
        -3,    -15,    -91,   -210,   -335,   -429,   -460,   -420,
      -320,   -191,    -73,     -5,     -9,    -86,   -213,   -353,
      -462,   -505,   -469,   -364,   -223,    -89,     -6,     -1,
       -77,   -214,   -369,   -494,   -552,   -521,   -412,   -258,
      -106,     -6,     11,    -64,   -210,   -382,   -527,   -600,
      -577,   -465,   -296,   -125,     -4,     26,    -47,   -201,
      -392,   -559,   -651,   -637,   -522,   -338,   -145,     -1,
        45,    -24,   -187,   -398,   -590,   -704,   -702,   -584,
      -385,   -166,      3,     69,      7,   -166,   -399,   -619,
      -759,   -773,   -654,   -437,   -190,     11,    100,     47,
      -136,   -393,   -648,   -818,   -851,   -732,   -496,   -216,
        21,    140,     98,    -94,   -381,   -674,   -882,   -939,
      -822,   -565,   -246,     36,    190,    165,    -38,   -358,
      -698,   -953,  -1040,   -927,   -645,   -280,     57,    257,
       252,     39,   -321,   -721,  -1034,  -1160,  -1055,   -744,
      -320,     86,    345,    370,    146,   -266,   -740,  -1131,
     -1311,  -1218,   -870,   -371,    127,    467,    534,    297,
      -181,   -757,  -1254,  -1511,  -1437,  -1043,   -440,    188,
       644,    774,    523,    -48,   -771,  -1426,  -1800,  -1760,
     -1299,   -542,    287,    926,   1161,    893,    178,   -783,
     -1699,  -2274,  -2302,  -1736,   -716,    466,   1441,   1882,
      1600,    626,   -791,  -2235,  -3243,  -3445,  -2687,  -1105,
       890,   2704,   3722,   3495,   1896,   -796,  -3912,  -6527,
     -7672,  -6578,  -2896,   3170,  10856,  18970,  26123,  31025,
     32767,  31025,  26123,  18970,  10856,   3170,  -2896,  -6578,
     -7672,  -6527,  -3912,   -796,   1896,   3495,   3722,   2704,
       890,  -1105,  -2687,  -3445,  -3243,  -2235,   -791,    626,
      1600,   1882,   1441,    466,   -716,  -1736,  -2302,  -2274,
     -1699,   -783,    178,    893,   1161,    926,    287,   -542,
     -1299,  -1760,  -1800,  -1426,   -771,    -48,    523,    774,
       644,    188,   -440,  -1043,  -1437,  -1511,  -1254,   -757,
      -181,    297,    534,    467,    127,   -371,   -870,  -1218,
     -1311,  -1131,   -740,   -266,    146,    370,    345,     86,
      -320,   -744,  -1055,  -1160,  -1034,   -721,   -321,     39,
       252,    257,     57,   -280,   -645,   -927,  -1040,   -953,
      -698,   -358,    -38,    165,    190,     36,   -246,   -565,
      -822,   -939,   -882,   -674,   -381,    -94,     98,    140,
        21,   -216,   -496,   -732,   -851,   -818,   -648,   -393,
      -136,     47,    100,     11,   -190,   -437,   -654,   -773,
      -759,   -619,   -399,   -166,      7,     69,      3,   -166,
      -385,   -584,   -702,   -704,   -590,   -398,   -187,    -24,
        45,     -1,   -145,   -338,   -522,   -637,   -651,   -559,
      -392,   -201,    -47,     26,     -4,   -125,   -296,   -465,
      -577,   -600,   -527,   -382,   -210,    -64,     11,     -6,
      -106,   -258,   -412,   -521,   -552,   -494,   -369,   -214,
       -77,     -1,     -6,    -89,   -223,   -364,   -469,   -505,
      -462,   -353,   -213,    -86,     -9,     -5,    -73,   -191,
      -320,   -420,   -460,   -429,   -335,   -210,    -91,    -15,
        -3,    -59,   -162,   -279,   -374,   -418,   -396,   -316,
      -204,    -94,    -19,     -2,    -45,   -135,   -242,   -332,
      -377,   -364,   -296,   -196,    -94,    -22,      1,    -33,
      -111,   -207,   -292,   -338,   -332,   -275,   -187,    -93,
       -23,      3,    -22,    -89,   -176,   -255,   -301,   -301,
      -254,   -176,    -90,    -23,      6,    -12,    -69,   -147,
      -220,   -267,   -271,   -233,   -164,    -86,    -22,      8,
        -3,    -52,   -121,   -189,   -234,   -243,   -212,   -152,
       -81,    -21,     10,      4,    -36,    -98,   -160,   -204,
      -216,   -192,   -140,    -76,    -20,     12,     11,    -23,
       -77,   -134,   -176,   -190,   -172,   -127,    -70,    -18,
        14,     16,    -11,    -59,   -111,   -151,   -167,   -153,
      -115,    -64,    -16,     16,     21,     -1,    -43,    -90,
      -127,   -144,   -135,   -103,    -58,    -13,     17,     24,
         7,    -29,    -71,   -106,   -124,   -118,    -92,    -52,
       -11,     18,     26,     13,    -17,    -55,    -88,   -106,
      -103,    -81,    -46,     -9,     18,     28,     19,     -7,
       -41,    -71,    -89,    -88,    -70,    -40,     -7,     18,
        29,     22,      1,    -29,    -56,    -74,    -75,    -61,
       -35,     -6,     18,     29,     25,      7,    -19,    -44,
       -60,    -64,    -52,    -30,     -4,     18,     29,     27,
        12,    -10,    -33,    -49,    -53,    -44,    -26,     -3,
        17,     29,     28,     16,     -4,    -24,    -39,    -44,
       -37,    -22,     -2,     16,     27,     28,     18,      2,
       -16,    -30,    -36,    -31,    -18,     -1,     16,     26,
        27,     20,      6,    -10,    -23,    -29,    -26,    -15,
         0,     15,     24,     27,     21,      9,     -5,    -17,
       -23,    -21,    -12,      1,     13,     23,     25,     21,
        11,     -1,    -12,    -18,    -17,    -10,      1,     12,
        21,     24,     21,     12,      2,     -8,    -13,    -13,
        -8,      1,     11,     19,     22,     20,     13,      4,
        -5,    -10,    -11,     -6,      1,     10,     17,     21,
        19,     14,      6,     -2,     -7,     -8,     -5,      2,
         9,     16,     19,     18,     14,      7,      0,     -5,
        -7,     -4,      2,      8,     14,     18,     18,     14,
         8,      1,     -3,     -5,     -3,      2,      8,     13,
        17,     17,     14,      8,      3,     -2,     -4,     -3,
         2,      7,     12,     16,     16,     14,      9,      4,
        -1,     -3,     -2,      2,      7,     12,     15,     16,
        14,     10,      5,      0,     -2,     -2,      2,      6,
        11
};

// ===== BANDPASS Filter =====
// fs = 48000 Hz
const q15_t FIR_FPBD_Coef_48K[Num_coef_FPBD + 1] = {
         9,     12,     13,     12,      9,      4,     -2,     -6,
        -9,     -9,     -8,     -4,      1,      7,     11,     13,
        12,      9,      5,     -1,     -6,    -10,    -11,    -10,
        -7,     -1,      4,      9,     12,     13,     11,      6,
         0,     -6,    -11,    -13,    -13,    -10,     -5,      2,
         8,     12,     13,     12,      7,      1,     -6,    -12,
       -16,    -17,    -14,     -9,     -2,      5,     11,     14,
        13,      9,      2,     -6,    -13,    -19,    -21,    -20,
       -14,     -7,      2,      9,     14,     14,     11,      4,
        -5,    -14,    -22,    -26,    -26,    -21,    -13,     -3,
         6,     13,     15,     13,      6,     -4,    -15,    -25,
       -32,    -33,    -29,    -21,    -10,      2,     11,     15,
        15,      8,     -3,    -16,    -29,    -38,    -41,    -39,
       -31,    -18,     -5,      7,     15,     16,     10,     -1,
       -16,    -32,    -44,    -51,    -50,    -43,    -29,    -14,
         2,     12,     16,     12,      1,    -16,    -34,    -50,
       -61,    -63,    -57,    -43,    -25,     -7,      8,     16,
        14,      3,    -15,    -36,    -56,    -71,    -77,    -73,
       -60,    -40,    -18,      1,     13,     15,      6,    -13,
       -37,    -61,    -81,    -92,    -91,    -79,    -58,    -33,
        -9,      8,     14,      8,    -10,    -37,    -66,    -91,
      -108,   -111,   -101,    -80,    -52,    -23,      1,     12,
        10,     -7,    -35,    -68,   -100,   -123,   -132,   -126,
      -105,    -74,    -40,    -11,      8,     10,     -4,    -32,
       -69,   -107,   -138,   -154,   -153,   -134,   -102,    -63,
       -26,      0,      9,     -1,    -29,    -69,   -112,   -151,
      -176,   -181,   -166,   -134,    -91,    -47,    -12,      6,
         2,    -24,    -65,   -115,   -162,   -197,   -211,   -201,
      -170,   -123,    -73,    -28,     -1,      3,    -18,    -60,
      -115,   -171,   -216,   -240,   -238,   -210,   -162,   -104,
       -50,    -11,      3,    -12,    -53,   -111,   -176,   -232,
      -268,   -276,   -253,   -205,   -142,    -78,    -27,     -1,
        -6,    -43,   -104,   -176,   -244,   -294,   -314,   -299,
      -254,   -186,   -112,    -48,     -8,     -2,    -32,    -93,
      -172,   -252,   -317,   -351,   -348,   -307,   -237,   -154,
       -76,    -20,      0,    -20,    -78,   -162,   -254,   -334,
      -386,   -396,   -364,   -294,   -204,   -111,    -38,      0,
        -8,    -60,   -147,   -249,   -346,   -417,   -444,   -423,
      -358,   -261,   -155,    -63,     -5,      4,    -39,   -125,
      -237,   -351,   -442,   -490,   -485,   -426,   -327,   -208,
       -96,    -15,     14,    -15,    -97,   -216,   -346,   -460,
      -532,   -547,   -499,   -400,   -270,   -138,    -33,     21,
        11,    -62,   -185,   -331,   -468,   -568,   -607,   -577,
      -482,   -344,   -191,    -59,     24,     38,    -22,   -144,
      -304,   -466,   -596,   -665,   -656,   -571,   -428,   -257,
       -95,     21,     65,     25,    -93,   -263,   -450,   -613,
      -717,   -737,   -669,   -525,   -336,   -143,     10,     90,
        77,    -29,   -206,   -418,   -617,   -762,   -818,   -773,
      -634,   -431,   -207,    -11,    112,    134,     47,   -132,
      -366,   -605,   -797,   -898,   -885,   -759,   -545,   -289,
       -46,    129,    196,    138,    -36,   -291,   -572,   -818,
      -975,  -1005,   -901,   -682,   -393,    -98,    139,    264,
       246,     85,   -186,   -512,   -822,  -1047,  -1135,  -1065,
      -848,   -528,   -173,    139,    338,    377,    241,    -42,
      -417,   -802,  -1112,  -1279,  -1260,  -1055,   -704,   -280,
       125,    421,    538,    446,    157,   -271,   -749,  -1171,
     -1444,  -1501,  -1324,   -943,   -436,     90,    518,    750,
       726,    443,    -47,   -645,  -1221,  -1647,  -1824,  -1700,
     -1291,   -676,     19,    642,   1051,   1146,    889,    320,
      -450,  -1261,  -1934,  -2312,  -2294,  -1862,  -1088,   -123,
       830,   1555,   1877,   1695,   1014,    -50,  -1290,  -2441,
     -3238,  -3472,  -3040,  -1977,   -459,   1221,   2701,   3627,
      3723,   2858,   1094,  -1308,  -3910,  -6166,  -7506,  -7437,
     -5639,  -2036,   3169,   9509,  16302,  22752,  28062,  31551,
     32767,  31551,  28062,  22752,  16302,   9509,   3169,  -2036,
     -5639,  -7437,  -7506,  -6166,  -3910,  -1308,   1094,   2858,
      3723,   3627,   2701,   1221,   -459,  -1977,  -3040,  -3472,
     -3238,  -2441,  -1290,    -50,   1014,   1695,   1877,   1555,
       830,   -123,  -1088,  -1862,  -2294,  -2312,  -1934,  -1261,
      -450,    320,    889,   1146,   1051,    642,     19,   -676,
     -1291,  -1700,  -1824,  -1647,  -1221,   -645,    -47,    443,
       726,    750,    518,     90,   -436,   -943,  -1324,  -1501,
     -1444,  -1171,   -749,   -271,    157,    446,    538,    421,
       125,   -280,   -704,  -1055,  -1260,  -1279,  -1112,   -802,
      -417,    -42,    241,    377,    338,    139,   -173,   -528,
      -848,  -1065,  -1135,  -1047,   -822,   -512,   -186,     85,
       246,    264,    139,    -98,   -393,   -682,   -901,  -1005,
      -975,   -818,   -572,   -291,    -36,    138,    196,    129,
       -46,   -289,   -545,   -759,   -885,   -898,   -797,   -605,
      -366,   -132,     47,    134,    112,    -11,   -207,   -431,
      -634,   -773,   -818,   -762,   -617,   -418,   -206,    -29,
        77,     90,     10,   -143,   -336,   -525,   -669,   -737,
      -717,   -613,   -450,   -263,    -93,     25,     65,     21,
       -95,   -257,   -428,   -571,   -656,   -665,   -596,   -466,
      -304,   -144,    -22,     38,     24,    -59,   -191,   -344,
      -482,   -577,   -607,   -568,   -468,   -331,   -185,    -62,
        11,     21,    -33,   -138,   -270,   -400,   -499,   -547,
      -532,   -460,   -346,   -216,    -97,    -15,     14,    -15,
       -96,   -208,   -327,   -426,   -485,   -490,   -442,   -351,
      -237,   -125,    -39,      4,     -5,    -63,   -155,   -261,
      -358,   -423,   -444,   -417,   -346,   -249,   -147,    -60,
        -8,      0,    -38,   -111,   -204,   -294,   -364,   -396,
      -386,   -334,   -254,   -162,    -78,    -20,      0,    -20,
       -76,   -154,   -237,   -307,   -348,   -351,   -317,   -252,
      -172,    -93,    -32,     -2,     -8,    -48,   -112,   -186,
      -254,   -299,   -314,   -294,   -244,   -176,   -104,    -43,
        -6,     -1,    -27,    -78,   -142,   -205,   -253,   -276,
      -268,   -232,   -176,   -111,    -53,    -12,      3,    -11,
       -50,   -104,   -162,   -210,   -238,   -240,   -216,   -171,
      -115,    -60,    -18,      3,     -1,    -28,    -73,   -123,
      -170,   -201,   -211,   -197,   -162,   -115,    -65,    -24,
         2,      6,    -12,    -47,    -91,   -134,   -166,   -181,
      -176,   -151,   -112,    -69,    -29,     -1,      9,      0,
       -26,    -63,   -102,   -134,   -153,   -154,   -138,   -107,
       -69,    -32,     -4,     10,      8,    -11,    -40,    -74,
      -105,   -126,   -132,   -123,   -100,    -68,    -35,     -7,
        10,     12,      1,    -23,    -52,    -80,   -101,   -111,
      -108,    -91,    -66,    -37,    -10,      8,     14,      8,
        -9,    -33,    -58,    -79,    -91,    -92,    -81,    -61,
       -37,    -13,      6,     15,     13,      1,    -18,    -40,
       -60,    -73,    -77,    -71,    -56,    -36,    -15,      3,
        14,     16,      8,     -7,    -25,    -43,    -57,    -63,
       -61,    -50,    -34,    -16,      1,     12,     16,     12,
         2,    -14,    -29,    -43,    -50,    -51,    -44,    -32,
       -16,     -1,     10,     16,     15,      7,     -5,    -18,
       -31,    -39,    -41,    -38,    -29,    -16,     -3,      8,
        15,     15,     11,      2,    -10,    -21,    -29,    -33,
       -32,    -25,    -15,     -4,      6,     13,     15,     13,
         6,     -3,    -13,    -21,    -26,    -26,    -22,    -14,
        -5,      4,     11,     14,     14,      9,      2,     -7,
       -14,    -20,    -21,    -19,    -13,     -6,      2,      9,
        13,     14,     11,      5,     -2,     -9,    -14,    -17,
       -16,    -12,     -6,      1,      7,     12,     13,     12,
         8,      2,     -5,    -10,    -13,    -13,    -11,     -6,
         0,      6,     11,     13,     12,      9,      4,     -1,
        -7,    -10,    -11,    -10,     -6,     -1,      5,      9,
        12,     13,     11,      7,      1,     -4,     -8,     -9,
        -9,     -6,     -2,      4,      9,     12,     13,     12,
         9
};

// ===== BAND_STOP Filter =====
// fs = 8000 Hz
const q15_t FIR_FRBD_Coef_8K[Num_coef_FRBD + 1] = {
         0,      0,      0,      0,      0,      0,      0,      0,
         0,      0,      0,      0,      0,      0,      0,      0,
         0,      0,      0,      0,      0,      0,      0,      0,
         0,      0,      0,      0,      0,      0,      0,      1,
         1,      1,      1,      1,      1,      1,      1,      1,
         1,      1,      1,      1,      1,      1,      1,      1,
         1,      1,      1,      1,      1,      1,      1,      2,
         2,      2,      2,      2,      2,      2,      2,      2,
         2,      2,      2,      2,      2,      2,      2,      2,
         2,      2,      2,      2,      2,      2,      2,      1,
         1,      1,      1,      1,      1,      1,      1,      1,
         1,      0,      0,      0,      0,      0,      0,     -1,
        -1,     -1,     -1,     -1,     -2,     -2,     -2,     -2,
        -3,     -3,     -3,     -3,     -4,     -4,     -4,     -5,
        -5,     -5,     -5,     -6,     -6,     -6,     -7,     -7,
        -7,     -7,     -8,     -8,     -8,     -8,     -9,     -9,
        -9,     -9,     -9,    -10,    -10,    -10,    -10,    -10,
       -10,    -10,    -10,    -10,    -10,    -10,    -10,    -10,
       -10,    -10,    -10,    -10,    -10,     -9,     -9,     -9,
        -9,     -8,     -8,     -8,     -7,     -7,     -6,     -6,
        -6,     -5,     -5,     -4,     -3,     -3,     -2,     -2,
        -1,      0,      0,      1,      2,      2,      3,      4,
         4,      5,      6,      6,      7,      8,      9,      9,
        10,     11,     11,     12,     13,     13,     14,     14,
        15,     16,     16,     17,     17,     18,     18,     18,
        19,     19,     19,     20,     20,     20,     20,     20,
        20,     20,     20,     20,     20,     20,     20,     20,
        19,     19,     19,     18,     18,     18,     17,     17,
        16,     16,     15,     14,     14,     13,     12,     12,
        11,     10,     10,      9,      8,      7,      7,      6,
         5,      4,      3,      3,      2,      1,      1,      0,
        -1,     -1,     -2,     -3,     -3,     -4,     -4,     -5,
        -5,     -5,     -6,     -6,     -6,     -6,     -7,     -7,
        -7,     -7,     -7,     -7,     -6,     -6,     -6,     -6,
        -6,     -5,     -5,     -4,     -4,     -3,     -3,     -2,
        -2,     -1,     -1,      0,      1,      1,      2,      3,
         3,      4,      5,      6,      6,      7,      7,      8,
         9,      9,     10,     10,     10,     11,     11,     11,
        11,     11,     11,     11,     11,     11,     11,     10,
        10,      9,      8,      8,      7,      6,      5,      3,
         2,      1,     -1,     -2,     -4,     -6,     -8,    -10,
       -12,    -14,    -16,    -19,    -21,    -23,    -26,    -29,
       -31,    -34,    -37,    -40,    -42,    -45,    -48,    -51,
       -54,    -57,    -60,    -63,    -65,    -68,    -71,    -73,
       -76,    -79,    -81,    -83,    -86,    -88,    -90,    -92,
       -93,    -95,    -96,    -98,    -99,    -99,   -100,   -101,
      -101,   -101,   -101,   -101,   -100,    -99,    -98,    -97,
       -95,    -93,    -91,    -89,    -86,    -84,    -81,    -77,
       -74,    -70,    -66,    -62,    -57,    -52,    -47,    -42,
       -37,    -31,    -25,    -19,    -13,     -6,      0,      7,
        14,     21,     28,     35,     42,     50,     57,     64,
        72,     79,     87,     94,    102,    109,    116,    124,
       131,    138,    145,    151,    158,    164,    170,    176,
       182,    187,    192,    197,    202,    206,    210,    214,
       217,    220,    222,    225,    226,    228,    229,    229,
       229,    229,    228,    227,    226,    224,    221,    218,
       215,    211,    207,    202,    197,    192,    186,    179,
       173,    166,    158,    150,    142,    134,    125,    116,
       106,     97,     87,     77,     66,     55,     45,     34,
        23,     11,      0,    -11,    -23,    -34,    -46,    -57,
       -69,    -80,    -91,   -102,   -113,   -124,   -135,   -146,
      -156,   -166,   -176,   -185,   -194,   -203,   -212,   -220,
      -228,   -235,   -243,   -249,   -255,   -261,   -266,   -271,
      -276,   -279,   -283,   -286,   -288,   -290,   -291,   -292,
     32767,   -292,   -291,   -290,   -288,   -286,   -283,   -279,
      -276,   -271,   -266,   -261,   -255,   -249,   -243,   -235,
      -228,   -220,   -212,   -203,   -194,   -185,   -176,   -166,
      -156,   -146,   -135,   -124,   -113,   -102,    -91,    -80,
       -69,    -57,    -46,    -34,    -23,    -11,      0,     11,
        23,     34,     45,     55,     66,     77,     87,     97,
       106,    116,    125,    134,    142,    150,    158,    166,
       173,    179,    186,    192,    197,    202,    207,    211,
       215,    218,    221,    224,    226,    227,    228,    229,
       229,    229,    229,    228,    226,    225,    222,    220,
       217,    214,    210,    206,    202,    197,    192,    187,
       182,    176,    170,    164,    158,    151,    145,    138,
       131,    124,    116,    109,    102,     94,     87,     79,
        72,     64,     57,     50,     42,     35,     28,     21,
        14,      7,      0,     -6,    -13,    -19,    -25,    -31,
       -37,    -42,    -47,    -52,    -57,    -62,    -66,    -70,
       -74,    -77,    -81,    -84,    -86,    -89,    -91,    -93,
       -95,    -97,    -98,    -99,   -100,   -101,   -101,   -101,
      -101,   -101,   -100,    -99,    -99,    -98,    -96,    -95,
       -93,    -92,    -90,    -88,    -86,    -83,    -81,    -79,
       -76,    -73,    -71,    -68,    -65,    -63,    -60,    -57,
       -54,    -51,    -48,    -45,    -42,    -40,    -37,    -34,
       -31,    -29,    -26,    -23,    -21,    -19,    -16,    -14,
       -12,    -10,     -8,     -6,     -4,     -2,     -1,      1,
         2,      3,      5,      6,      7,      8,      8,      9,
        10,     10,     11,     11,     11,     11,     11,     11,
        11,     11,     11,     11,     10,     10,     10,      9,
         9,      8,      7,      7,      6,      6,      5,      4,
         3,      3,      2,      1,      1,      0,     -1,     -1,
        -2,     -2,     -3,     -3,     -4,     -4,     -5,     -5,
        -6,     -6,     -6,     -6,     -6,     -7,     -7,     -7,
        -7,     -7,     -7,     -6,     -6,     -6,     -6,     -5,
        -5,     -5,     -4,     -4,     -3,     -3,     -2,     -1,
        -1,      0,      1,      1,      2,      3,      3,      4,
         5,      6,      7,      7,      8,      9,     10,     10,
        11,     12,     12,     13,     14,     14,     15,     16,
        16,     17,     17,     18,     18,     18,     19,     19,
        19,     20,     20,     20,     20,     20,     20,     20,
        20,     20,     20,     20,     20,     20,     19,     19,
        19,     18,     18,     18,     17,     17,     16,     16,
        15,     14,     14,     13,     13,     12,     11,     11,
        10,      9,      9,      8,      7,      6,      6,      5,
         4,      4,      3,      2,      2,      1,      0,      0,
        -1,     -2,     -2,     -3,     -3,     -4,     -5,     -5,
        -6,     -6,     -6,     -7,     -7,     -8,     -8,     -8,
        -9,     -9,     -9,     -9,    -10,    -10,    -10,    -10,
       -10,    -10,    -10,    -10,    -10,    -10,    -10,    -10,
       -10,    -10,    -10,    -10,    -10,    -10,     -9,     -9,
        -9,     -9,     -9,     -8,     -8,     -8,     -8,     -7,
        -7,     -7,     -7,     -6,     -6,     -6,     -5,     -5,
        -5,     -5,     -4,     -4,     -4,     -3,     -3,     -3,
        -3,     -2,     -2,     -2,     -2,     -1,     -1,     -1,
        -1,     -1,      0,      0,      0,      0,      0,      0,
         1,      1,      1,      1,      1,      1,      1,      1,
         1,      1,      2,      2,      2,      2,      2,      2,
         2,      2,      2,      2,      2,      2,      2,      2,
         2,      2,      2,      2,      2,      2,      2,      2,
         2,      2,      1,      1,      1,      1,      1,      1,
         1,      1,      1,      1,      1,      1,      1,      1,
         1,      1,      1,      1,      1,      1,      1,      1,
         1,      1,      0,      0,      0,      0,      0,      0,
         0,      0,      0,      0,      0,      0,      0,      0,
         0,      0,      0,      0,      0,      0,      0,      0,
         0,      0,      0,      0,      0,      0,      0,      0,
         0
};

// ===== BAND_STOP Filter =====
// fs = 16000 Hz
const q15_t FIR_FRBD_Coef_16K[Num_coef_FRBD + 1] = {
         0,      0,      1,      1,      1,      1,      1,      1,
         1,      1,      1,      1,      1,      1,      1,      1,
         1,      1,      1,      2,      2,      2,      2,      2,
         2,      2,      2,      2,      2,      2,      2,      3,
         3,      3,      3,      3,      3,      3,      3,      3,
         3,      4,      4,      4,      4,      4,      4,      4,
         4,      4,      5,      5,      5,      5,      5,      5,
         5,      5,      5,      5,      6,      6,      6,      6,
         6,      6,      6,      6,      6,      6,      6,      7,
         7,      7,      7,      7,      7,      7,      7,      7,
         7,      7,      7,      7,      7,      7,      7,      7,
         7,      7,      7,      7,      7,      7,      7,      7,
         7,      7,      7,      7,      7,      7,      7,      6,
         6,      6,      6,      6,      6,      6,      6,      5,
         5,      5,      5,      5,      4,      4,      4,      4,
         4,      3,      3,      3,      2,      2,      2,      2,
         1,      1,      1,      0,      0,     -1,     -1,     -1,
        -2,     -2,     -2,     -3,     -3,     -4,     -4,     -5,
        -5,     -6,     -6,     -7,     -7,     -8,     -8,     -9,
        -9,    -10,    -10,    -11,    -11,    -12,    -12,    -13,
       -14,    -14,    -15,    -15,    -16,    -16,    -17,    -18,
       -18,    -19,    -19,    -20,    -21,    -21,    -22,    -22,
       -23,    -24,    -24,    -25,    -25,    -26,    -27,    -27,
       -28,    -28,    -29,    -30,    -30,    -31,    -31,    -32,
       -32,    -33,    -33,    -34,    -34,    -35,    -35,    -36,
       -36,    -37,    -37,    -38,    -38,    -38,    -39,    -39,
       -40,    -40,    -40,    -40,    -41,    -41,    -41,    -42,
       -42,    -42,    -42,    -42,    -42,    -43,    -43,    -43,
       -43,    -43,    -43,    -43,    -43,    -43,    -43,    -43,
       -42,    -42,    -42,    -42,    -42,    -41,    -41,    -41,
       -40,    -40,    -40,    -39,    -39,    -38,    -38,    -37,
       -37,    -36,    -36,    -35,    -34,    -34,    -33,    -32,
       -31,    -30,    -30,    -29,    -28,    -27,    -26,    -25,
       -24,    -23,    -22,    -21,    -20,    -19,    -18,    -16,
       -15,    -14,    -13,    -12,    -10,     -9,     -8,     -6,
        -5,     -3,     -2,     -1,      1,      2,      4,      5,
         7,      8,     10,     11,     13,     15,     16,     18,
        19,     21,     23,     24,     26,     28,     29,     31,
        33,     34,     36,     38,     39,     41,     43,     44,
        46,     48,     49,     51,     53,     54,     56,     58,
        59,     61,     62,     64,     65,     67,     69,     70,
        71,     73,     74,     76,     77,     79,     80,     81,
        83,     84,     85,     86,     87,     89,     90,     91,
        92,     93,     94,     95,     96,     97,     97,     98,
        99,    100,    100,    101,    102,    102,    103,    103,
       104,    104,    104,    104,    105,    105,    105,    105,
       105,    105,    105,    105,    105,    105,    104,    104,
       104,    103,    103,    102,    102,    101,    100,    100,
        99,     98,     97,     96,     95,     94,     93,     92,
        91,     90,     88,     87,     86,     84,     83,     81,
        80,     78,     77,     75,     73,     71,     69,     68,
        66,     64,     62,     60,     58,     56,     53,     51,
        49,     47,     45,     42,     40,     38,     35,     33,
        30,     28,     25,     23,     20,     18,     15,     13,
        10,      7,      5,      2,     -1,     -3,     -6,     -9,
       -11,    -14,    -17,    -19,    -22,    -25,    -28,    -30,
       -33,    -36,    -38,    -41,    -44,    -46,    -49,    -51,
       -54,    -57,    -59,    -62,    -64,    -67,    -69,    -72,
       -74,    -77,    -79,    -81,    -84,    -86,    -88,    -90,
       -93,    -95,    -97,    -99,   -101,   -103,   -105,   -107,
      -108,   -110,   -112,   -114,   -115,   -117,   -119,   -120,
      -121,   -123,   -124,   -125,   -127,   -128,   -129,   -130,
      -131,   -132,   -133,   -134,   -135,   -135,   -136,   -136,
      -137,   -137,   -138,   -138,   -139,   -139,   -139,   -139,
     32767,   -139,   -139,   -139,   -139,   -138,   -138,   -137,
      -137,   -136,   -136,   -135,   -135,   -134,   -133,   -132,
      -131,   -130,   -129,   -128,   -127,   -125,   -124,   -123,
      -121,   -120,   -119,   -117,   -115,   -114,   -112,   -110,
      -108,   -107,   -105,   -103,   -101,    -99,    -97,    -95,
       -93,    -90,    -88,    -86,    -84,    -81,    -79,    -77,
       -74,    -72,    -69,    -67,    -64,    -62,    -59,    -57,
       -54,    -51,    -49,    -46,    -44,    -41,    -38,    -36,
       -33,    -30,    -28,    -25,    -22,    -19,    -17,    -14,
       -11,     -9,     -6,     -3,     -1,      2,      5,      7,
        10,     13,     15,     18,     20,     23,     25,     28,
        30,     33,     35,     38,     40,     42,     45,     47,
        49,     51,     53,     56,     58,     60,     62,     64,
        66,     68,     69,     71,     73,     75,     77,     78,
        80,     81,     83,     84,     86,     87,     88,     90,
        91,     92,     93,     94,     95,     96,     97,     98,
        99,    100,    100,    101,    102,    102,    103,    103,
       104,    104,    104,    105,    105,    105,    105,    105,
       105,    105,    105,    105,    105,    104,    104,    104,
       104,    103,    103,    102,    102,    101,    100,    100,
        99,     98,     97,     97,     96,     95,     94,     93,
        92,     91,     90,     89,     87,     86,     85,     84,
        83,     81,     80,     79,     77,     76,     74,     73,
        71,     70,     69,     67,     65,     64,     62,     61,
        59,     58,     56,     54,     53,     51,     49,     48,
        46,     44,     43,     41,     39,     38,     36,     34,
        33,     31,     29,     28,     26,     24,     23,     21,
        19,     18,     16,     15,     13,     11,     10,      8,
         7,      5,      4,      2,      1,     -1,     -2,     -3,
        -5,     -6,     -8,     -9,    -10,    -12,    -13,    -14,
       -15,    -16,    -18,    -19,    -20,    -21,    -22,    -23,
       -24,    -25,    -26,    -27,    -28,    -29,    -30,    -30,
       -31,    -32,    -33,    -34,    -34,    -35,    -36,    -36,
       -37,    -37,    -38,    -38,    -39,    -39,    -40,    -40,
       -40,    -41,    -41,    -41,    -42,    -42,    -42,    -42,
       -42,    -43,    -43,    -43,    -43,    -43,    -43,    -43,
       -43,    -43,    -43,    -43,    -42,    -42,    -42,    -42,
       -42,    -42,    -41,    -41,    -41,    -40,    -40,    -40,
       -40,    -39,    -39,    -38,    -38,    -38,    -37,    -37,
       -36,    -36,    -35,    -35,    -34,    -34,    -33,    -33,
       -32,    -32,    -31,    -31,    -30,    -30,    -29,    -28,
       -28,    -27,    -27,    -26,    -25,    -25,    -24,    -24,
       -23,    -22,    -22,    -21,    -21,    -20,    -19,    -19,
       -18,    -18,    -17,    -16,    -16,    -15,    -15,    -14,
       -14,    -13,    -12,    -12,    -11,    -11,    -10,    -10,
        -9,     -9,     -8,     -8,     -7,     -7,     -6,     -6,
        -5,     -5,     -4,     -4,     -3,     -3,     -2,     -2,
        -2,     -1,     -1,     -1,      0,      0,      1,      1,
         1,      2,      2,      2,      2,      3,      3,      3,
         4,      4,      4,      4,      4,      5,      5,      5,
         5,      5,      6,      6,      6,      6,      6,      6,
         6,      6,      7,      7,      7,      7,      7,      7,
         7,      7,      7,      7,      7,      7,      7,      7,
         7,      7,      7,      7,      7,      7,      7,      7,
         7,      7,      7,      7,      7,      7,      7,      7,
         7,      7,      6,      6,      6,      6,      6,      6,
         6,      6,      6,      6,      6,      5,      5,      5,
         5,      5,      5,      5,      5,      5,      5,      4,
         4,      4,      4,      4,      4,      4,      4,      4,
         3,      3,      3,      3,      3,      3,      3,      3,
         3,      3,      2,      2,      2,      2,      2,      2,
         2,      2,      2,      2,      2,      2,      1,      1,
         1,      1,      1,      1,      1,      1,      1,      1,
         1,      1,      1,      1,      1,      1,      1,      0,
         0
};

// ===== BAND_STOP Filter =====
// fs = 24000 Hz
const q15_t FIR_FRBD_Coef_22K[Num_coef_FRBD + 1] = {
        -4,     -5,     -5,     -5,     -5,     -5,     -6,     -6,
        -6,     -6,     -6,     -7,     -7,     -7,     -7,     -7,
        -8,     -8,     -8,     -8,     -9,     -9,     -9,     -9,
        -9,    -10,    -10,    -10,    -10,    -11,    -11,    -11,
       -11,    -12,    -12,    -12,    -12,    -12,    -13,    -13,
       -13,    -13,    -14,    -14,    -14,    -14,    -15,    -15,
       -15,    -15,    -16,    -16,    -16,    -16,    -17,    -17,
       -17,    -17,    -17,    -18,    -18,    -18,    -18,    -19,
       -19,    -19,    -19,    -19,    -20,    -20,    -20,    -20,
       -20,    -21,    -21,    -21,    -21,    -21,    -21,    -22,
       -22,    -22,    -22,    -22,    -22,    -22,    -23,    -23,
       -23,    -23,    -23,    -23,    -23,    -23,    -23,    -24,
       -24,    -24,    -24,    -24,    -24,    -24,    -24,    -24,
       -24,    -24,    -24,    -24,    -24,    -24,    -24,    -24,
       -24,    -24,    -24,    -24,    -24,    -24,    -23,    -23,
       -23,    -23,    -23,    -23,    -23,    -23,    -22,    -22,
       -22,    -22,    -22,    -21,    -21,    -21,    -21,    -21,
       -20,    -20,    -20,    -20,    -19,    -19,    -19,    -18,
       -18,    -18,    -17,    -17,    -17,    -16,    -16,    -16,
       -15,    -15,    -14,    -14,    -13,    -13,    -13,    -12,
       -12,    -11,    -11,    -10,    -10,     -9,     -9,     -8,
        -7,     -7,     -6,     -6,     -5,     -5,     -4,     -3,
        -3,     -2,     -2,     -1,      0,      0,      1,      2,
         2,      3,      4,      4,      5,      6,      7,      7,
         8,      9,      9,     10,     11,     12,     12,     13,
        14,     15,     16,     16,     17,     18,     19,     20,
        20,     21,     22,     23,     24,     24,     25,     26,
        27,     28,     28,     29,     30,     31,     32,     33,
        33,     34,     35,     36,     37,     38,     38,     39,
        40,     41,     42,     42,     43,     44,     45,     46,
        46,     47,     48,     49,     49,     50,     51,     52,
        53,     53,     54,     55,     55,     56,     57,     58,
        58,     59,     60,     60,     61,     62,     62,     63,
        63,     64,     65,     65,     66,     66,     67,     67,
        68,     69,     69,     70,     70,     70,     71,     71,
        72,     72,     73,     73,     73,     74,     74,     74,
        75,     75,     75,     76,     76,     76,     76,     76,
        77,     77,     77,     77,     77,     77,     77,     77,
        77,     78,     78,     78,     78,     77,     77,     77,
        77,     77,     77,     77,     77,     76,     76,     76,
        76,     76,     75,     75,     75,     74,     74,     74,
        73,     73,     72,     72,     71,     71,     70,     70,
        69,     69,     68,     68,     67,     66,     66,     65,
        64,     64,     63,     62,     61,     61,     60,     59,
        58,     57,     56,     56,     55,     54,     53,     52,
        51,     50,     49,     48,     47,     46,     45,     44,
        43,     41,     40,     39,     38,     37,     36,     35,
        33,     32,     31,     30,     28,     27,     26,     25,
        23,     22,     21,     19,     18,     17,     15,     14,
        13,     11,     10,      9,      7,      6,      4,      3,
         2,      0,     -1,     -3,     -4,     -5,     -7,     -8,
       -10,    -11,    -13,    -14,    -16,    -17,    -19,    -20,
       -21,    -23,    -24,    -26,    -27,    -29,    -30,    -32,
       -33,    -34,    -36,    -37,    -39,    -40,    -42,    -43,
       -44,    -46,    -47,    -48,    -50,    -51,    -53,    -54,
       -55,    -57,    -58,    -59,    -61,    -62,    -63,    -64,
       -66,    -67,    -68,    -69,    -70,    -72,    -73,    -74,
       -75,    -76,    -77,    -79,    -80,    -81,    -82,    -83,
       -84,    -85,    -86,    -87,    -88,    -89,    -90,    -91,
       -91,    -92,    -93,    -94,    -95,    -96,    -96,    -97,
       -98,    -99,    -99,   -100,   -101,   -101,   -102,   -102,
      -103,   -104,   -104,   -105,   -105,   -105,   -106,   -106,
      -107,   -107,   -107,   -108,   -108,   -108,   -109,   -109,
      -109,   -109,   -109,   -109,   -110,   -110,   -110,   -110,
     32767,   -110,   -110,   -110,   -110,   -109,   -109,   -109,
      -109,   -109,   -109,   -108,   -108,   -108,   -107,   -107,
      -107,   -106,   -106,   -105,   -105,   -105,   -104,   -104,
      -103,   -102,   -102,   -101,   -101,   -100,    -99,    -99,
       -98,    -97,    -96,    -96,    -95,    -94,    -93,    -92,
       -91,    -91,    -90,    -89,    -88,    -87,    -86,    -85,
       -84,    -83,    -82,    -81,    -80,    -79,    -77,    -76,
       -75,    -74,    -73,    -72,    -70,    -69,    -68,    -67,
       -66,    -64,    -63,    -62,    -61,    -59,    -58,    -57,
       -55,    -54,    -53,    -51,    -50,    -48,    -47,    -46,
       -44,    -43,    -42,    -40,    -39,    -37,    -36,    -34,
       -33,    -32,    -30,    -29,    -27,    -26,    -24,    -23,
       -21,    -20,    -19,    -17,    -16,    -14,    -13,    -11,
       -10,     -8,     -7,     -5,     -4,     -3,     -1,      0,
         2,      3,      4,      6,      7,      9,     10,     11,
        13,     14,     15,     17,     18,     19,     21,     22,
        23,     25,     26,     27,     28,     30,     31,     32,
        33,     35,     36,     37,     38,     39,     40,     41,
        43,     44,     45,     46,     47,     48,     49,     50,
        51,     52,     53,     54,     55,     56,     56,     57,
        58,     59,     60,     61,     61,     62,     63,     64,
        64,     65,     66,     66,     67,     68,     68,     69,
        69,     70,     70,     71,     71,     72,     72,     73,
        73,     74,     74,     74,     75,     75,     75,     76,
        76,     76,     76,     76,     77,     77,     77,     77,
        77,     77,     77,     77,     78,     78,     78,     78,
        77,     77,     77,     77,     77,     77,     77,     77,
        77,     76,     76,     76,     76,     76,     75,     75,
        75,     74,     74,     74,     73,     73,     73,     72,
        72,     71,     71,     70,     70,     70,     69,     69,
        68,     67,     67,     66,     66,     65,     65,     64,
        63,     63,     62,     62,     61,     60,     60,     59,
        58,     58,     57,     56,     55,     55,     54,     53,
        53,     52,     51,     50,     49,     49,     48,     47,
        46,     46,     45,     44,     43,     42,     42,     41,
        40,     39,     38,     38,     37,     36,     35,     34,
        33,     33,     32,     31,     30,     29,     28,     28,
        27,     26,     25,     24,     24,     23,     22,     21,
        20,     20,     19,     18,     17,     16,     16,     15,
        14,     13,     12,     12,     11,     10,      9,      9,
         8,      7,      7,      6,      5,      4,      4,      3,
         2,      2,      1,      0,      0,     -1,     -2,     -2,
        -3,     -3,     -4,     -5,     -5,     -6,     -6,     -7,
        -7,     -8,     -9,     -9,    -10,    -10,    -11,    -11,
       -12,    -12,    -13,    -13,    -13,    -14,    -14,    -15,
       -15,    -16,    -16,    -16,    -17,    -17,    -17,    -18,
       -18,    -18,    -19,    -19,    -19,    -20,    -20,    -20,
       -20,    -21,    -21,    -21,    -21,    -21,    -22,    -22,
       -22,    -22,    -22,    -23,    -23,    -23,    -23,    -23,
       -23,    -23,    -23,    -24,    -24,    -24,    -24,    -24,
       -24,    -24,    -24,    -24,    -24,    -24,    -24,    -24,
       -24,    -24,    -24,    -24,    -24,    -24,    -24,    -24,
       -24,    -24,    -23,    -23,    -23,    -23,    -23,    -23,
       -23,    -23,    -23,    -22,    -22,    -22,    -22,    -22,
       -22,    -22,    -21,    -21,    -21,    -21,    -21,    -21,
       -20,    -20,    -20,    -20,    -20,    -19,    -19,    -19,
       -19,    -19,    -18,    -18,    -18,    -18,    -17,    -17,
       -17,    -17,    -17,    -16,    -16,    -16,    -16,    -15,
       -15,    -15,    -15,    -14,    -14,    -14,    -14,    -13,
       -13,    -13,    -13,    -12,    -12,    -12,    -12,    -12,
       -11,    -11,    -11,    -11,    -10,    -10,    -10,    -10,
        -9,     -9,     -9,     -9,     -9,     -8,     -8,     -8,
        -8,     -7,     -7,     -7,     -7,     -7,     -6,     -6,
        -6,     -6,     -6,     -5,     -5,     -5,     -5,     -5,
        -4
};

// ===== BAND_STOP Filter =====
// fs = 40000 Hz
const q15_t FIR_FRBD_Coef_44K[Num_coef_FRBD + 1] = {
        12,     12,     13,     13,     13,     13,     14,     14,
        14,     14,     15,     15,     15,     15,     16,     16,
        16,     16,     17,     17,     17,     17,     18,     18,
        18,     18,     19,     19,     19,     20,     20,     20,
        20,     21,     21,     21,     21,     22,     22,     22,
        22,     23,     23,     23,     24,     24,     24,     24,
        25,     25,     25,     25,     26,     26,     26,     26,
        27,     27,     27,     28,     28,     28,     28,     29,
        29,     29,     29,     30,     30,     30,     30,     31,
        31,     31,     31,     32,     32,     32,     32,     33,
        33,     33,     33,     34,     34,     34,     34,     35,
        35,     35,     35,     36,     36,     36,     36,     37,
        37,     37,     37,     37,     38,     38,     38,     38,
        38,     39,     39,     39,     39,     39,     40,     40,
        40,     40,     40,     41,     41,     41,     41,     41,
        42,     42,     42,     42,     42,     42,     42,     43,
        43,     43,     43,     43,     43,     44,     44,     44,
        44,     44,     44,     44,     44,     44,     45,     45,
        45,     45,     45,     45,     45,     45,     45,     45,
        45,     46,     46,     46,     46,     46,     46,     46,
        46,     46,     46,     46,     46,     46,     46,     46,
        46,     46,     46,     46,     46,     46,     46,     46,
        46,     46,     46,     46,     46,     46,     46,     46,
        46,     46,     46,     46,     46,     46,     45,     45,
        45,     45,     45,     45,     45,     45,     45,     45,
        44,     44,     44,     44,     44,     44,     44,     44,
        43,     43,     43,     43,     43,     43,     42,     42,
        42,     42,     42,     41,     41,     41,     41,     41,
        40,     40,     40,     40,     39,     39,     39,     39,
        38,     38,     38,     38,     37,     37,     37,     36,
        36,     36,     35,     35,     35,     35,     34,     34,
        34,     33,     33,     33,     32,     32,     32,     31,
        31,     30,     30,     30,     29,     29,     29,     28,
        28,     27,     27,     27,     26,     26,     25,     25,
        25,     24,     24,     23,     23,     22,     22,     21,
        21,     21,     20,     20,     19,     19,     18,     18,
        17,     17,     16,     16,     15,     15,     14,     14,
        13,     13,     12,     12,     11,     11,     10,     10,
         9,      9,      8,      8,      7,      7,      6,      6,
         5,      5,      4,      3,      3,      2,      2,      1,
         1,      0,      0,     -1,     -2,     -2,     -3,     -3,
        -4,     -4,     -5,     -5,     -6,     -7,     -7,     -8,
        -8,     -9,     -9,    -10,    -11,    -11,    -12,    -12,
       -13,    -14,    -14,    -15,    -15,    -16,    -16,    -17,
       -18,    -18,    -19,    -19,    -20,    -20,    -21,    -22,
       -22,    -23,    -23,    -24,    -25,    -25,    -26,    -26,
       -27,    -27,    -28,    -29,    -29,    -30,    -30,    -31,
       -31,    -32,    -33,    -33,    -34,    -34,    -35,    -35,
       -36,    -37,    -37,    -38,    -38,    -39,    -39,    -40,
       -40,    -41,    -41,    -42,    -42,    -43,    -44,    -44,
       -45,    -45,    -46,    -46,    -47,    -47,    -48,    -48,
       -49,    -49,    -50,    -50,    -51,    -51,    -52,    -52,
       -53,    -53,    -54,    -54,    -54,    -55,    -55,    -56,
       -56,    -57,    -57,    -58,    -58,    -58,    -59,    -59,
       -60,    -60,    -61,    -61,    -61,    -62,    -62,    -63,
       -63,    -63,    -64,    -64,    -64,    -65,    -65,    -66,
       -66,    -66,    -67,    -67,    -67,    -68,    -68,    -68,
       -69,    -69,    -69,    -69,    -70,    -70,    -70,    -71,
       -71,    -71,    -71,    -72,    -72,    -72,    -72,    -73,
       -73,    -73,    -73,    -73,    -74,    -74,    -74,    -74,
       -74,    -75,    -75,    -75,    -75,    -75,    -75,    -76,
       -76,    -76,    -76,    -76,    -76,    -76,    -76,    -77,
       -77,    -77,    -77,    -77,    -77,    -77,    -77,    -77,
       -77,    -77,    -77,    -77,    -77,    -77,    -77,    -77,
     32767,    -77,    -77,    -77,    -77,    -77,    -77,    -77,
       -77,    -77,    -77,    -77,    -77,    -77,    -77,    -77,
       -77,    -77,    -76,    -76,    -76,    -76,    -76,    -76,
       -76,    -76,    -75,    -75,    -75,    -75,    -75,    -75,
       -74,    -74,    -74,    -74,    -74,    -73,    -73,    -73,
       -73,    -73,    -72,    -72,    -72,    -72,    -71,    -71,
       -71,    -71,    -70,    -70,    -70,    -69,    -69,    -69,
       -69,    -68,    -68,    -68,    -67,    -67,    -67,    -66,
       -66,    -66,    -65,    -65,    -64,    -64,    -64,    -63,
       -63,    -63,    -62,    -62,    -61,    -61,    -61,    -60,
       -60,    -59,    -59,    -58,    -58,    -58,    -57,    -57,
       -56,    -56,    -55,    -55,    -54,    -54,    -54,    -53,
       -53,    -52,    -52,    -51,    -51,    -50,    -50,    -49,
       -49,    -48,    -48,    -47,    -47,    -46,    -46,    -45,
       -45,    -44,    -44,    -43,    -42,    -42,    -41,    -41,
       -40,    -40,    -39,    -39,    -38,    -38,    -37,    -37,
       -36,    -35,    -35,    -34,    -34,    -33,    -33,    -32,
       -31,    -31,    -30,    -30,    -29,    -29,    -28,    -27,
       -27,    -26,    -26,    -25,    -25,    -24,    -23,    -23,
       -22,    -22,    -21,    -20,    -20,    -19,    -19,    -18,
       -18,    -17,    -16,    -16,    -15,    -15,    -14,    -14,
       -13,    -12,    -12,    -11,    -11,    -10,     -9,     -9,
        -8,     -8,     -7,     -7,     -6,     -5,     -5,     -4,
        -4,     -3,     -3,     -2,     -2,     -1,      0,      0,
         1,      1,      2,      2,      3,      3,      4,      5,
         5,      6,      6,      7,      7,      8,      8,      9,
         9,     10,     10,     11,     11,     12,     12,     13,
        13,     14,     14,     15,     15,     16,     16,     17,
        17,     18,     18,     19,     19,     20,     20,     21,
        21,     21,     22,     22,     23,     23,     24,     24,
        25,     25,     25,     26,     26,     27,     27,     27,
        28,     28,     29,     29,     29,     30,     30,     30,
        31,     31,     32,     32,     32,     33,     33,     33,
        34,     34,     34,     35,     35,     35,     35,     36,
        36,     36,     37,     37,     37,     38,     38,     38,
        38,     39,     39,     39,     39,     40,     40,     40,
        40,     41,     41,     41,     41,     41,     42,     42,
        42,     42,     42,     43,     43,     43,     43,     43,
        43,     44,     44,     44,     44,     44,     44,     44,
        44,     45,     45,     45,     45,     45,     45,     45,
        45,     45,     45,     46,     46,     46,     46,     46,
        46,     46,     46,     46,     46,     46,     46,     46,
        46,     46,     46,     46,     46,     46,     46,     46,
        46,     46,     46,     46,     46,     46,     46,     46,
        46,     46,     46,     46,     46,     46,     46,     46,
        45,     45,     45,     45,     45,     45,     45,     45,
        45,     45,     45,     44,     44,     44,     44,     44,
        44,     44,     44,     44,     43,     43,     43,     43,
        43,     43,     42,     42,     42,     42,     42,     42,
        42,     41,     41,     41,     41,     41,     40,     40,
        40,     40,     40,     39,     39,     39,     39,     39,
        38,     38,     38,     38,     38,     37,     37,     37,
        37,     37,     36,     36,     36,     36,     35,     35,
        35,     35,     34,     34,     34,     34,     33,     33,
        33,     33,     32,     32,     32,     32,     31,     31,
        31,     31,     30,     30,     30,     30,     29,     29,
        29,     29,     28,     28,     28,     28,     27,     27,
        27,     26,     26,     26,     26,     25,     25,     25,
        25,     24,     24,     24,     24,     23,     23,     23,
        22,     22,     22,     22,     21,     21,     21,     21,
        20,     20,     20,     20,     19,     19,     19,     18,
        18,     18,     18,     17,     17,     17,     17,     16,
        16,     16,     16,     15,     15,     15,     15,     14,
        14,     14,     14,     13,     13,     13,     13,     12,
        12
};

// ===== BAND_STOP Filter =====
// fs = 48000 Hz
const q15_t FIR_FRBD_Coef_48K[Num_coef_FRBD + 1] = {
        20,     20,     21,     21,     21,     21,     21,     22,
        22,     22,     22,     22,     22,     23,     23,     23,
        23,     23,     23,     24,     24,     24,     24,     24,
        24,     25,     25,     25,     25,     25,     25,     26,
        26,     26,     26,     26,     26,     27,     27,     27,
        27,     27,     27,     27,     28,     28,     28,     28,
        28,     28,     28,     29,     29,     29,     29,     29,
        29,     29,     29,     30,     30,     30,     30,     30,
        30,     30,     30,     31,     31,     31,     31,     31,
        31,     31,     31,     31,     31,     32,     32,     32,
        32,     32,     32,     32,     32,     32,     32,     32,
        33,     33,     33,     33,     33,     33,     33,     33,
        33,     33,     33,     33,     33,     33,     33,     33,
        34,     34,     34,     34,     34,     34,     34,     34,
        34,     34,     34,     34,     34,     34,     34,     34,
        34,     34,     34,     34,     34,     34,     34,     34,
        34,     34,     34,     34,     34,     34,     34,     34,
        34,     34,     34,     34,     34,     34,     34,     34,
        34,     33,     33,     33,     33,     33,     33,     33,
        33,     33,     33,     33,     33,     33,     33,     33,
        32,     32,     32,     32,     32,     32,     32,     32,
        32,     32,     31,     31,     31,     31,     31,     31,
        31,     31,     31,     30,     30,     30,     30,     30,
        30,     30,     29,     29,     29,     29,     29,     29,
        28,     28,     28,     28,     28,     28,     27,     27,
        27,     27,     27,     26,     26,     26,     26,     26,
        25,     25,     25,     25,     25,     24,     24,     24,
        24,     24,     23,     23,     23,     23,     22,     22,
        22,     22,     21,     21,     21,     21,     20,     20,
        20,     20,     19,     19,     19,     19,     18,     18,
        18,     18,     17,     17,     17,     16,     16,     16,
        16,     15,     15,     15,     14,     14,     14,     14,
        13,     13,     13,     12,     12,     12,     11,     11,
        11,     10,     10,     10,      9,      9,      9,      9,
         8,      8,      8,      7,      7,      7,      6,      6,
         6,      5,      5,      5,      4,      4,      3,      3,
         3,      2,      2,      2,      1,      1,      1,      0,
         0,      0,     -1,     -1,     -1,     -2,     -2,     -2,
        -3,     -3,     -4,     -4,     -4,     -5,     -5,     -5,
        -6,     -6,     -6,     -7,     -7,     -8,     -8,     -8,
        -9,     -9,     -9,    -10,    -10,    -10,    -11,    -11,
       -12,    -12,    -12,    -13,    -13,    -13,    -14,    -14,
       -15,    -15,    -15,    -16,    -16,    -16,    -17,    -17,
       -17,    -18,    -18,    -19,    -19,    -19,    -20,    -20,
       -20,    -21,    -21,    -21,    -22,    -22,    -23,    -23,
       -23,    -24,    -24,    -24,    -25,    -25,    -25,    -26,
       -26,    -26,    -27,    -27,    -27,    -28,    -28,    -28,
       -29,    -29,    -29,    -30,    -30,    -30,    -31,    -31,
       -31,    -32,    -32,    -32,    -33,    -33,    -33,    -34,
       -34,    -34,    -35,    -35,    -35,    -36,    -36,    -36,
       -37,    -37,    -37,    -37,    -38,    -38,    -38,    -39,
       -39,    -39,    -39,    -40,    -40,    -40,    -41,    -41,
       -41,    -41,    -42,    -42,    -42,    -43,    -43,    -43,
       -43,    -44,    -44,    -44,    -44,    -45,    -45,    -45,
       -45,    -45,    -46,    -46,    -46,    -46,    -47,    -47,
       -47,    -47,    -47,    -48,    -48,    -48,    -48,    -48,
       -49,    -49,    -49,    -49,    -49,    -50,    -50,    -50,
       -50,    -50,    -50,    -51,    -51,    -51,    -51,    -51,
       -51,    -52,    -52,    -52,    -52,    -52,    -52,    -52,
       -53,    -53,    -53,    -53,    -53,    -53,    -53,    -53,
       -53,    -54,    -54,    -54,    -54,    -54,    -54,    -54,
       -54,    -54,    -54,    -54,    -54,    -55,    -55,    -55,
       -55,    -55,    -55,    -55,    -55,    -55,    -55,    -55,
       -55,    -55,    -55,    -55,    -55,    -55,    -55,    -55,
     32767,    -55,    -55,    -55,    -55,    -55,    -55,    -55,
       -55,    -55,    -55,    -55,    -55,    -55,    -55,    -55,
       -55,    -55,    -55,    -55,    -54,    -54,    -54,    -54,
       -54,    -54,    -54,    -54,    -54,    -54,    -54,    -54,
       -53,    -53,    -53,    -53,    -53,    -53,    -53,    -53,
       -53,    -52,    -52,    -52,    -52,    -52,    -52,    -52,
       -51,    -51,    -51,    -51,    -51,    -51,    -50,    -50,
       -50,    -50,    -50,    -50,    -49,    -49,    -49,    -49,
       -49,    -48,    -48,    -48,    -48,    -48,    -47,    -47,
       -47,    -47,    -47,    -46,    -46,    -46,    -46,    -45,
       -45,    -45,    -45,    -45,    -44,    -44,    -44,    -44,
       -43,    -43,    -43,    -43,    -42,    -42,    -42,    -41,
       -41,    -41,    -41,    -40,    -40,    -40,    -39,    -39,
       -39,    -39,    -38,    -38,    -38,    -37,    -37,    -37,
       -37,    -36,    -36,    -36,    -35,    -35,    -35,    -34,
       -34,    -34,    -33,    -33,    -33,    -32,    -32,    -32,
       -31,    -31,    -31,    -30,    -30,    -30,    -29,    -29,
       -29,    -28,    -28,    -28,    -27,    -27,    -27,    -26,
       -26,    -26,    -25,    -25,    -25,    -24,    -24,    -24,
       -23,    -23,    -23,    -22,    -22,    -21,    -21,    -21,
       -20,    -20,    -20,    -19,    -19,    -19,    -18,    -18,
       -17,    -17,    -17,    -16,    -16,    -16,    -15,    -15,
       -15,    -14,    -14,    -13,    -13,    -13,    -12,    -12,
       -12,    -11,    -11,    -10,    -10,    -10,     -9,     -9,
        -9,     -8,     -8,     -8,     -7,     -7,     -6,     -6,
        -6,     -5,     -5,     -5,     -4,     -4,     -4,     -3,
        -3,     -2,     -2,     -2,     -1,     -1,     -1,      0,
         0,      0,      1,      1,      1,      2,      2,      2,
         3,      3,      3,      4,      4,      5,      5,      5,
         6,      6,      6,      7,      7,      7,      8,      8,
         8,      9,      9,      9,      9,     10,     10,     10,
        11,     11,     11,     12,     12,     12,     13,     13,
        13,     14,     14,     14,     14,     15,     15,     15,
        16,     16,     16,     16,     17,     17,     17,     18,
        18,     18,     18,     19,     19,     19,     19,     20,
        20,     20,     20,     21,     21,     21,     21,     22,
        22,     22,     22,     23,     23,     23,     23,     24,
        24,     24,     24,     24,     25,     25,     25,     25,
        25,     26,     26,     26,     26,     26,     27,     27,
        27,     27,     27,     28,     28,     28,     28,     28,
        28,     29,     29,     29,     29,     29,     29,     30,
        30,     30,     30,     30,     30,     30,     31,     31,
        31,     31,     31,     31,     31,     31,     31,     32,
        32,     32,     32,     32,     32,     32,     32,     32,
        32,     33,     33,     33,     33,     33,     33,     33,
        33,     33,     33,     33,     33,     33,     33,     33,
        34,     34,     34,     34,     34,     34,     34,     34,
        34,     34,     34,     34,     34,     34,     34,     34,
        34,     34,     34,     34,     34,     34,     34,     34,
        34,     34,     34,     34,     34,     34,     34,     34,
        34,     34,     34,     34,     34,     34,     34,     34,
        34,     33,     33,     33,     33,     33,     33,     33,
        33,     33,     33,     33,     33,     33,     33,     33,
        33,     32,     32,     32,     32,     32,     32,     32,
        32,     32,     32,     32,     31,     31,     31,     31,
        31,     31,     31,     31,     31,     31,     30,     30,
        30,     30,     30,     30,     30,     30,     29,     29,
        29,     29,     29,     29,     29,     29,     28,     28,
        28,     28,     28,     28,     28,     27,     27,     27,
        27,     27,     27,     27,     26,     26,     26,     26,
        26,     26,     25,     25,     25,     25,     25,     25,
        24,     24,     24,     24,     24,     24,     23,     23,
        23,     23,     23,     23,     22,     22,     22,     22,
        22,     22,     21,     21,     21,     21,     21,     20,
        20
};

/* USER CODE END PV */

void SystemClock_Config(void);

/* USER CODE BEGIN 0 */

/**
 * @brief Converts a Q15 array to a 12-bit DAC buffer
 * @param in: Input Q15 data array
 * @param out: Output DAC buffer
 * @param len: Number of elements to convert
 */
void convert_q15_to_dac_buffer(q15_t *in, uint16_t *out, uint16_t len) {
	for (uint16_t i = 0; i < len; i++) {
		int32_t val = ((int32_t) in[i] * 4095) / 32767;
		if (val < 0)
			val = 0;
		else if (val > 4095)
			val = 4095;
		out[i] = (uint16_t) val;
	}
}

/**
 * @brief Processes half of the ADC buffer: converts to Q15, applies processing, and prepares DAC output
 * @param adc_in: Input ADC buffer
 * @param q15_out: Intermediate Q15 buffer
 * @param dac_out: Output DAC buffer
 * @param offset: Offset to select first or second half of buffer
 */
void process_buffer_half(uint16_t *adc_in, q15_t *q15_out, uint16_t *dac_out,
		uint16_t offset) {
	uint32_t start = DWT->CYCCNT; // Start cycle counter for performance profiling

	// Convert ADC 12-bit values to Q15 format
	for (uint16_t i = 0; i < BUFFER_SIZE / 2; i++) {
		q15_out[i + offset] = (q15_t) (((int32_t) adc_in[i + offset] * 32767)
				/ 4095);
	}

	arm_fir_q15(&Filtro, &q15_out[offset], &q15_out[offset], BUFFER_SIZE/2);

	// Convert processed Q15 data to DAC output format
	convert_q15_to_dac_buffer(&q15_out[offset], &dac_out[offset],
	BUFFER_SIZE / 2);

	time = DWT->CYCCNT - start; // Measure processing time in CPU cycles
}

/**
 * @brief DMA Half Transfer Complete Callback for ADC
 */
void HAL_ADC_ConvHalfCpltCallback(ADC_HandleTypeDef *hadc) {
	if (hadc->Instance == ADC1) {
		process_buffer_half(adc_buffer, q15_buffer, dac_buffer, 0);
	}
}

/**
 * @brief DMA Transfer Complete Callback for ADC
 */
void HAL_ADC_ConvCpltCallback(ADC_HandleTypeDef *hadc) {
	if (hadc->Instance == ADC1) {
		process_buffer_half(adc_buffer, q15_buffer, dac_buffer,
		BUFFER_SIZE / 2);
	}
}

/**
 * @brief GPIO interrupt callback for switching sampling frequencies or stopping acquisition
 *        Cycles through 6 modes on button press (pin: SW_FS) and switching type filter through
 *        4 modes, BP, HP, BP and BS on button press (pin: SW_MODE_1)
 */
void HAL_GPIO_EXTI_Callback(uint16_t GPIO_Pin) {

	if (GPIO_Pin == SW_FS_Pin) {
		fs_mode = (fs_mode + 1) % 6;

		// Stop timer before reconfiguring
		__HAL_TIM_DISABLE(&htim2);

		switch (fs_mode) {
		case 0:
			__HAL_TIM_SET_AUTORELOAD(&htim2, FS_8K);        // 8 kHz
			HAL_GPIO_WritePin(LED_B_GPIO_Port, LED_B_Pin, GPIO_PIN_SET); // Blue
			HAL_GPIO_WritePin(LED_R_GPIO_Port, LED_R_Pin, GPIO_PIN_RESET);
			HAL_GPIO_WritePin(LED_G_GPIO_Port, LED_G_Pin, GPIO_PIN_RESET);
			break;
		case 1:
			__HAL_TIM_SET_AUTORELOAD(&htim2, FS_8K / 2);    // ~16 kHz
			HAL_GPIO_WritePin(LED_B_GPIO_Port, LED_B_Pin, GPIO_PIN_RESET);
			HAL_GPIO_WritePin(LED_R_GPIO_Port, LED_R_Pin, GPIO_PIN_SET);  // Red
			HAL_GPIO_WritePin(LED_G_GPIO_Port, LED_G_Pin, GPIO_PIN_RESET);
			break;
		case 2:
			__HAL_TIM_SET_AUTORELOAD(&htim2, FS_8K / 3);    // ~24 kHz
			HAL_GPIO_WritePin(LED_B_GPIO_Port, LED_B_Pin, GPIO_PIN_RESET);
			HAL_GPIO_WritePin(LED_R_GPIO_Port, LED_R_Pin, GPIO_PIN_RESET);
			HAL_GPIO_WritePin(LED_G_GPIO_Port, LED_G_Pin, GPIO_PIN_SET); // Green
			break;
		case 3:
			__HAL_TIM_SET_AUTORELOAD(&htim2, FS_8K / 5);    // ~40 kHz
			HAL_GPIO_WritePin(LED_B_GPIO_Port, LED_B_Pin, GPIO_PIN_RESET);
			HAL_GPIO_WritePin(LED_R_GPIO_Port, LED_R_Pin, GPIO_PIN_SET); // Red + Green = Yellow
			HAL_GPIO_WritePin(LED_G_GPIO_Port, LED_G_Pin, GPIO_PIN_SET);
			break;
		case 4:
			__HAL_TIM_SET_AUTORELOAD(&htim2, FS_8K / 6);    // ~48 kHz
			HAL_GPIO_WritePin(LED_B_GPIO_Port, LED_B_Pin, GPIO_PIN_SET); // Blue + Red = Purple
			HAL_GPIO_WritePin(LED_R_GPIO_Port, LED_R_Pin, GPIO_PIN_SET);
			HAL_GPIO_WritePin(LED_G_GPIO_Port, LED_G_Pin, GPIO_PIN_RESET);
			break;
		case 5:
			// Stop all activity
			HAL_GPIO_WritePin(LED_B_GPIO_Port, LED_B_Pin, GPIO_PIN_RESET); // All off
			HAL_GPIO_WritePin(LED_R_GPIO_Port, LED_R_Pin, GPIO_PIN_RESET);
			HAL_GPIO_WritePin(LED_G_GPIO_Port, LED_G_Pin, GPIO_PIN_RESET);
			__HAL_TIM_DISABLE(&htim2);
			memset(&Filtro, 0, sizeof(Filtro));
			return;
		}
		// Force change filter type when switch frequency sample
		HAL_GPIO_EXTI_Callback(SW_MODE_1_Pin);

		// Reset and enable timer
		__HAL_TIM_SET_COUNTER(&htim2, 0);
		TIM2->EGR = TIM_EGR_UG;
		__HAL_TIM_ENABLE(&htim2);
	}

	if (GPIO_Pin == SW_MODE_1_Pin) {
		filter_type = (filter_type + 1) % 4;

		switch (fs_mode) {
		case 0: // 8 kHz

			switch (filter_type) {
			case 0:
				memset(FPB_status, 0, sizeof(FPB_status));
				arm_fir_init_q15(&Filtro, Num_coef_FPB+1, (q15_t *)FIR_FPB_Coef_8K, FPB_status, BUFFER_SIZE/2);
				break;
			case 1:
				memset(FPA_status, 0, sizeof(FPA_status));
				arm_fir_init_q15(&Filtro, Num_coef_FPA+1, (q15_t *)FIR_FPA_Coef_8K, FPA_status, BUFFER_SIZE/2);
				break;
			case 2:
				memset(FPBD_status, 0, sizeof(FPBD_status));
				arm_fir_init_q15(&Filtro, Num_coef_FPBD+1, (q15_t *)FIR_FPBD_Coef_8K, FPBD_status, BUFFER_SIZE/2);
				break;
			case 3:
				memset(FRBD_status, 0, sizeof(FRBD_status));
				arm_fir_init_q15(&Filtro, Num_coef_FRBD+1, (q15_t *)FIR_FRBD_Coef_8K, FRBD_status, BUFFER_SIZE/2);
				break;
			}
			break;

		case 1: // 16 kHz
			switch (filter_type) {
			case 0:
				memset(FPB_status, 0, sizeof(FPB_status));
				arm_fir_init_q15(&Filtro, Num_coef_FPB+1, (q15_t *)FIR_FPB_Coef_16K, FPB_status, BUFFER_SIZE/2);
				break;
			case 1:
				memset(FPA_status, 0, sizeof(FPA_status));
				arm_fir_init_q15(&Filtro, Num_coef_FPA+1, (q15_t *)FIR_FPA_Coef_16K, FPA_status, BUFFER_SIZE/2);
				break;
			case 2:
				memset(FPBD_status, 0, sizeof(FPBD_status));
				arm_fir_init_q15(&Filtro, Num_coef_FPBD+1, (q15_t *)FIR_FPBD_Coef_16K, FPBD_status, BUFFER_SIZE/2);
				break;
			case 3:
				memset(FRBD_status, 0, sizeof(FRBD_status));
				arm_fir_init_q15(&Filtro, Num_coef_FRBD+1, (q15_t *)FIR_FRBD_Coef_16K, FRBD_status, BUFFER_SIZE/2);
				break;
			}
			break;

		case 2: // 24 kHz
			switch (filter_type) {
			case 0:
				memset(FPB_status, 0, sizeof(FPB_status));
				arm_fir_init_q15(&Filtro, Num_coef_FPB+1, (q15_t *)FIR_FPB_Coef_22K, FPB_status, BUFFER_SIZE/2);
				break;
			case 1:
				memset(FPA_status, 0, sizeof(FPA_status));
				arm_fir_init_q15(&Filtro, Num_coef_FPA+1, (q15_t *)FIR_FPA_Coef_22K, FPA_status, BUFFER_SIZE/2);
				break;
			case 2:
				memset(FPBD_status, 0, sizeof(FPBD_status));
				arm_fir_init_q15(&Filtro, Num_coef_FPBD+1, (q15_t *)FIR_FPBD_Coef_22K, FPBD_status, BUFFER_SIZE/2);
				break;
			case 3:
				memset(FRBD_status, 0, sizeof(FRBD_status));
				arm_fir_init_q15(&Filtro, Num_coef_FRBD+1, (q15_t *)FIR_FRBD_Coef_22K, FRBD_status, BUFFER_SIZE/2);
				break;
			}
			break;

		case 3: // 40 kHz
			switch (filter_type) {
			case 0:
				memset(FPB_status, 0, sizeof(FPB_status));
				arm_fir_init_q15(&Filtro, Num_coef_FPB+1, (q15_t *)FIR_FPB_Coef_44K, FPB_status, BUFFER_SIZE/2);
				break;
			case 1:
				memset(FPA_status, 0, sizeof(FPA_status));
				arm_fir_init_q15(&Filtro, Num_coef_FPA+1, (q15_t *)FIR_FPA_Coef_44K, FPA_status, BUFFER_SIZE/2);
				break;
			case 2:
				memset(FPBD_status, 0, sizeof(FPBD_status));
				arm_fir_init_q15(&Filtro, Num_coef_FPBD+1, (q15_t *)FIR_FPBD_Coef_44K, FPBD_status, BUFFER_SIZE/2);
				break;
			case 3:
				memset(FRBD_status, 0, sizeof(FRBD_status));
				arm_fir_init_q15(&Filtro, Num_coef_FRBD+1, (q15_t *)FIR_FRBD_Coef_44K, FRBD_status, BUFFER_SIZE/2);
				break;
			}
			break;

		case 4: // 48 kHz
			switch (filter_type) {
			case 0:
				memset(FPB_status, 0, sizeof(FPB_status));
				arm_fir_init_q15(&Filtro, Num_coef_FPB+1, (q15_t *)FIR_FPB_Coef_48K, FPB_status, BUFFER_SIZE/2);
				break;
			case 1:
				memset(FPA_status, 0, sizeof(FPA_status));
				arm_fir_init_q15(&Filtro, Num_coef_FPA+1, (q15_t *)FIR_FPA_Coef_48K, FPA_status, BUFFER_SIZE/2);
				break;
			case 2:
				memset(FPBD_status, 0, sizeof(FPBD_status));
				arm_fir_init_q15(&Filtro, Num_coef_FPBD+1, (q15_t *)FIR_FPBD_Coef_48K, FPBD_status, BUFFER_SIZE/2);
				break;
			case 3:
				memset(FRBD_status, 0, sizeof(FRBD_status));
				arm_fir_init_q15(&Filtro, Num_coef_FRBD+1, (q15_t *)FIR_FRBD_Coef_48K, FRBD_status, BUFFER_SIZE/2);
				break;
			}
			break;
		}
	}
}
/* USER CODE END 0 */

int main(void) {

	/* USER CODE BEGIN 1 */
	// Enable DWT cycle counter for profiling purposes
	CoreDebug->DEMCR |= CoreDebug_DEMCR_TRCENA_Msk;
	DWT->CYCCNT = 0;
	DWT->CTRL |= DWT_CTRL_CYCCNTENA_Msk;
	/* USER CODE END 1 */

	/* MCU Configuration--------------------------------------------------------*/

	/* Reset of all peripherals, Initializes the Flash interface and the Systick. */
	HAL_Init();

	/* Configure the system clock */
	SystemClock_Config();

	/* Initialize all configured peripherals */
	MX_GPIO_Init();
	MX_DMA_Init();
	MX_ADC1_Init();
	MX_TIM2_Init();
	MX_DAC_Init();
	/* USER CODE BEGIN 2 */

	HAL_GPIO_WritePin(LED_B_GPIO_Port, LED_B_Pin, GPIO_PIN_SET);    // Blue
	HAL_GPIO_WritePin(LED_R_GPIO_Port, LED_R_Pin, GPIO_PIN_RESET);
	HAL_GPIO_WritePin(LED_G_GPIO_Port, LED_G_Pin, GPIO_PIN_RESET);

	// Start base timer
	HAL_TIM_Base_Start(&htim2);

	// Start DAC in DMA mode
	HAL_DAC_Start_DMA(&hdac, DAC_CHANNEL_1, (uint32_t*) dac_buffer,
	BUFFER_SIZE, DAC_ALIGN_12B_R);

	// Start ADC in DMA mode
	HAL_ADC_Start_DMA(&hadc1, (uint32_t*) adc_buffer, BUFFER_SIZE);

	memset(FPB_status, 0, sizeof(FPB_status));
	arm_fir_init_q15(&Filtro, Num_coef_FPB+1, FIR_FPB_Coef_8K, FPB_status, BUFFER_SIZE/2);

	/* USER CODE END 2 */

	/* Infinite loop */
	while (1) {

		/* USER CODE BEGIN 3 */
		// Main loop intentionally left empty. All processing handled via DMA callbacks and interrupts.
	}
	/* USER CODE END 3 */
}

void SystemClock_Config(void) {
	RCC_OscInitTypeDef RCC_OscInitStruct = { 0 };
	RCC_ClkInitTypeDef RCC_ClkInitStruct = { 0 };

	/** Configure the main internal regulator output voltage
	 */
	__HAL_RCC_PWR_CLK_ENABLE();
	__HAL_PWR_VOLTAGESCALING_CONFIG(PWR_REGULATOR_VOLTAGE_SCALE1);

	/** Initializes the RCC Oscillators according to the specified parameters
	 * in the RCC_OscInitTypeDef structure.
	 */
	RCC_OscInitStruct.OscillatorType = RCC_OSCILLATORTYPE_HSI;
	RCC_OscInitStruct.HSIState = RCC_HSI_ON;
	RCC_OscInitStruct.HSICalibrationValue = RCC_HSICALIBRATION_DEFAULT;
	RCC_OscInitStruct.PLL.PLLState = RCC_PLL_ON;
	RCC_OscInitStruct.PLL.PLLSource = RCC_PLLSOURCE_HSI;
	RCC_OscInitStruct.PLL.PLLM = 8;
	RCC_OscInitStruct.PLL.PLLN = 180;
	RCC_OscInitStruct.PLL.PLLP = RCC_PLLP_DIV2;
	RCC_OscInitStruct.PLL.PLLQ = 2;
	RCC_OscInitStruct.PLL.PLLR = 2;
	if (HAL_RCC_OscConfig(&RCC_OscInitStruct) != HAL_OK) {
		Error_Handler();
	}

	/** Activate the Over-Drive mode
	 */
	if (HAL_PWREx_EnableOverDrive() != HAL_OK) {
		Error_Handler();
	}

	/** Initializes the CPU, AHB and APB buses clocks
	 */
	RCC_ClkInitStruct.ClockType = RCC_CLOCKTYPE_HCLK | RCC_CLOCKTYPE_SYSCLK
			| RCC_CLOCKTYPE_PCLK1 | RCC_CLOCKTYPE_PCLK2;
	RCC_ClkInitStruct.SYSCLKSource = RCC_SYSCLKSOURCE_PLLCLK;
	RCC_ClkInitStruct.AHBCLKDivider = RCC_SYSCLK_DIV1;
	RCC_ClkInitStruct.APB1CLKDivider = RCC_HCLK_DIV4;
	RCC_ClkInitStruct.APB2CLKDivider = RCC_HCLK_DIV2;

	if (HAL_RCC_ClockConfig(&RCC_ClkInitStruct, FLASH_LATENCY_5) != HAL_OK) {
		Error_Handler();
	}
}

void Error_Handler(void) {
	/* USER CODE BEGIN Error_Handler_Debug */
	// Stay in infinite loop on error
	__disable_irq();
	while (1) {
	}
	/* USER CODE END Error_Handler_Debug */
}

#ifdef  USE_FULL_ASSERT
/**
  * @brief  Reports the name of the source file and the source line number
  *         where the assert_param error has occurred.
  * @param  file: pointer to the source file name
  * @param  line: assert_param error line source number
  * @retval None
  */
void assert_failed(uint8_t *file, uint32_t line)
{
  /* USER CODE BEGIN 6 */
  // Custom assert handler (optional user-defined implementation)
  /* USER CODE END 6 */
}
#endif /* USE_FULL_ASSERT */
